[part 2 of 2: packages /BMW/Boardnet/Clusters/CommunicationClusters to /BMW/Boardnet/Pdus/PDUs]
AUTOSAR XML (schema 4-2-2)
package /BMW/Boardnet/Clusters/CommunicationClusters  (continued)
  flexray cluster A_FlexRay:  (continued)
    flexray physical channel A_FlexRay: comm-connectors=con_EPS_FibexID_0b7e5e09c061465d913e8968ece3cded, channel-name=CHANNEL-A  (continued)
      frame xcpdynamic254_2: from EPS, category=XCP_RUNTIME_CONFIGURED, frame-length=254, flexray-absolutely-scheduled-timing{communication-cycle=cycle-repetition={base-cycle=0, cycle-repetition=CYCLE-REPETITION-1}, slot-id=295}, allow-dynamic-l-sdu-length=false, payload-preamble-indicator=false  # XCP-Bereich dynamic 254 Bytes 2 | XCP-Frame (Runtime-Configured) für die Kommunikation zwischen Master und Slaves. Maximal zulässige Größe ist 254 Bytes. Wichtig: Die FIBEX-Framegröße stellt keine Spezifikation dar sondern bildet lediglich die protokolltechnisch maximal erlaubte Größe. Die Framegröße muss durch den Anwender im a2l-File festgelegt werden. Dabei muss auch die ECU-spezifische Controllerkonfiguration beachtet werden. Sende-/Empfangsbeziehungen im FIBEX dürfen nicht ausgewertet werden und sind ebenfalls keine verbindliche Spezifikation.
        general purpose i pdu xcpdynamic254_2: category=XCP, length=254  # XCP-Bereich dynamic 254 Bytes 2 | Die PDU (254 Byte lang) hat ebenso keine inhaltliche Verbindlichkeit.
      frame xcpdynamic254_3: from EPS, category=XCP_RUNTIME_CONFIGURED, frame-length=254, flexray-absolutely-scheduled-timing{communication-cycle=cycle-repetition={base-cycle=0, cycle-repetition=CYCLE-REPETITION-1}, slot-id=296}, allow-dynamic-l-sdu-length=false, payload-preamble-indicator=false  # XCP-Bereich dynamic 254 Bytes 3 | XCP-Frame (Runtime-Configured) für die Kommunikation zwischen Master und Slaves. Maximal zulässige Größe ist 254 Bytes. Wichtig: Die FIBEX-Framegröße stellt keine Spezifikation dar sondern bildet lediglich die protokolltechnisch maximal erlaubte Größe. Die Framegröße muss durch den Anwender im a2l-File festgelegt werden. Dabei muss auch die ECU-spezifische Controllerkonfiguration beachtet werden. Sende-/Empfangsbeziehungen im FIBEX dürfen nicht ausgewertet werden und sind ebenfalls keine verbindliche Spezifikation.
        general purpose i pdu xcpdynamic254_3: category=XCP, length=254  # XCP-Bereich dynamic 254 Bytes 3 | Die PDU (254 Byte lang) hat ebenso keine inhaltliche Verbindlichkeit.
      frame xcpdynamic254_4: from EPS, category=XCP_RUNTIME_CONFIGURED, frame-length=254, flexray-absolutely-scheduled-timing{communication-cycle=cycle-repetition={base-cycle=0, cycle-repetition=CYCLE-REPETITION-1}, slot-id=297}, allow-dynamic-l-sdu-length=false, payload-preamble-indicator=false  # XCP-Bereich dynamic 254 Bytes 4 | XCP-Frame (Runtime-Configured) für die Kommunikation zwischen Master und Slaves. Maximal zulässige Größe ist 254 Bytes. Wichtig: Die FIBEX-Framegröße stellt keine Spezifikation dar sondern bildet lediglich die protokolltechnisch maximal erlaubte Größe. Die Framegröße muss durch den Anwender im a2l-File festgelegt werden. Dabei muss auch die ECU-spezifische Controllerkonfiguration beachtet werden. Sende-/Empfangsbeziehungen im FIBEX dürfen nicht ausgewertet werden und sind ebenfalls keine verbindliche Spezifikation.
        general purpose i pdu xcpdynamic254_4: category=XCP, length=254  # XCP-Bereich dynamic 254 Bytes 4 | Die PDU (254 Byte lang) hat ebenso keine inhaltliche Verbindlichkeit.
      frame xcpdynamic254_5: from EPS, category=XCP_RUNTIME_CONFIGURED, frame-length=254, flexray-absolutely-scheduled-timing{communication-cycle=cycle-repetition={base-cycle=0, cycle-repetition=CYCLE-REPETITION-1}, slot-id=298}, allow-dynamic-l-sdu-length=false, payload-preamble-indicator=false  # XCP-Bereich dynamic 254 Bytes 5 | XCP-Frame (Runtime-Configured) für die Kommunikation zwischen Master und Slaves. Maximal zulässige Größe ist 254 Bytes. Wichtig: Die FIBEX-Framegröße stellt keine Spezifikation dar sondern bildet lediglich die protokolltechnisch maximal erlaubte Größe. Die Framegröße muss durch den Anwender im a2l-File festgelegt werden. Dabei muss auch die ECU-spezifische Controllerkonfiguration beachtet werden. Sende-/Empfangsbeziehungen im FIBEX dürfen nicht ausgewertet werden und sind ebenfalls keine verbindliche Spezifikation.
        general purpose i pdu xcpdynamic254_5: category=XCP, length=254  # XCP-Bereich dynamic 254 Bytes 5 | Die PDU (254 Byte lang) hat ebenso keine inhaltliche Verbindlichkeit.
      frame xcpdynamic254_6: from EPS, category=XCP_RUNTIME_CONFIGURED, frame-length=254, flexray-absolutely-scheduled-timing{communication-cycle=cycle-repetition={base-cycle=0, cycle-repetition=CYCLE-REPETITION-1}, slot-id=299}, allow-dynamic-l-sdu-length=false, payload-preamble-indicator=false  # XCP-Bereich dynamic 254 Bytes 6 | XCP-Frame (Runtime-Configured) für die Kommunikation zwischen Master und Slaves. Maximal zulässige Größe ist 254 Bytes. Wichtig: Die FIBEX-Framegröße stellt keine Spezifikation dar sondern bildet lediglich die protokolltechnisch maximal erlaubte Größe. Die Framegröße muss durch den Anwender im a2l-File festgelegt werden. Dabei muss auch die ECU-spezifische Controllerkonfiguration beachtet werden. Sende-/Empfangsbeziehungen im FIBEX dürfen nicht ausgewertet werden und sind ebenfalls keine verbindliche Spezifikation.
        general purpose i pdu xcpdynamic254_6: category=XCP, length=254  # XCP-Bereich dynamic 254 Bytes 6 | Die PDU (254 Byte lang) hat ebenso keine inhaltliche Verbindlichkeit.
      frame xcpdynamic254_7: from EPS, category=XCP_RUNTIME_CONFIGURED, frame-length=254, flexray-absolutely-scheduled-timing{communication-cycle=cycle-repetition={base-cycle=0, cycle-repetition=CYCLE-REPETITION-1}, slot-id=300}, allow-dynamic-l-sdu-length=false, payload-preamble-indicator=false  # XCP-Bereich dynamic 254 Bytes 7 | XCP-Frame (Runtime-Configured) für die Kommunikation zwischen Master und Slaves. Maximal zulässige Größe ist 254 Bytes. Wichtig: Die FIBEX-Framegröße stellt keine Spezifikation dar sondern bildet lediglich die protokolltechnisch maximal erlaubte Größe. Die Framegröße muss durch den Anwender im a2l-File festgelegt werden. Dabei muss auch die ECU-spezifische Controllerkonfiguration beachtet werden. Sende-/Empfangsbeziehungen im FIBEX dürfen nicht ausgewertet werden und sind ebenfalls keine verbindliche Spezifikation.
        general purpose i pdu xcpdynamic254_7: category=XCP, length=254  # XCP-Bereich dynamic 254 Bytes 7 | Die PDU (254 Byte lang) hat ebenso keine inhaltliche Verbindlichkeit.
      frame xcpdynamic254_8: from EPS, category=XCP_RUNTIME_CONFIGURED, frame-length=254, flexray-absolutely-scheduled-timing{communication-cycle=cycle-repetition={base-cycle=0, cycle-repetition=CYCLE-REPETITION-1}, slot-id=301}, allow-dynamic-l-sdu-length=false, payload-preamble-indicator=false  # XCP-Bereich dynamic 254 Bytes 8 | XCP-Frame (Runtime-Configured) für die Kommunikation zwischen Master und Slaves. Maximal zulässige Größe ist 254 Bytes. Wichtig: Die FIBEX-Framegröße stellt keine Spezifikation dar sondern bildet lediglich die protokolltechnisch maximal erlaubte Größe. Die Framegröße muss durch den Anwender im a2l-File festgelegt werden. Dabei muss auch die ECU-spezifische Controllerkonfiguration beachtet werden. Sende-/Empfangsbeziehungen im FIBEX dürfen nicht ausgewertet werden und sind ebenfalls keine verbindliche Spezifikation.
        general purpose i pdu xcpdynamic254_8: category=XCP, length=254  # XCP-Bereich dynamic 254 Bytes 8 | Die PDU (254 Byte lang) hat ebenso keine inhaltliche Verbindlichkeit.
      frame FR_DBG_EPS: from EPS, category=APPLICATION, frame-length=58, flexray-absolutely-scheduled-timing{communication-cycle=cycle-repetition={base-cycle=0, cycle-repetition=CYCLE-REPETITION-1}, slot-id=315}, allow-dynamic-l-sdu-length=false, payload-preamble-indicator=false  # FlexRay Debug EPS | Dieser Frame enthält nur Debugging-Informationen, die ausschließlich während der Entwicklungszeit übertragen werden dürfen. Kein Serienumfang! Der Frame darf nicht für andere Zwecke als Debugging verwendet werden. Für Messzweck ist ausschließlich XCP zu verwenden. Jedes FlexRay Steuergerät ist einen Debug-Frame zugewiesen. Falls kein Bedarf vorhanden, soll dieser Debug-Frame nicht gesendet werden. Das Senden der Frame soll über ein Codierschalter abschaltbar sein. Der Codierschalter sollte wie folgt definiert werden: C_DebugFrame_FR Die in dieser Frame enthaltene Signale dürfen von den Fachstellen geändert werden. Die hier vorgegebene maximale Länge und Zykluszeit gilt für den Basis-Modus (z.B. FIT Fahrzeug oder SA909). Der Basis-Modus darf ohne Abstimmung nicht erweitert werden (dient zur Sicherstellung der Bandbreite im FIT-Fahrzeuge). Falls die Notwendigkeit besteht mehr Daten schneller zu senden, darf dies in einem Extended-Modus stattfinden. Dieser Extended Modus muss über den Debug-Codierschalter ein- und ausschaltbar sein. Für den Codierschalter sollte folgende Codierung verwendet werden 0: nichts senden 1: senden Basis-Modus 2: senden Extended-Modus_1 (optional) Die Umsetzung des Modus Erweitert ist optional.
        multiplexed i pdu FR_DBG_EPS:  # FlexRay Debug EPS
          length=58
          dynamic-part{segment-position{segment-byte-order=little-endian, segment-length=464, segment-position=0}, dynamic-part-alternatives=[{i-pdu=DBG_EPS_BS_MOD_58_BYTE, initial-dynamic-part=true, selector-field-code=1}, {i-pdu=DBG_EPS_MOD_EXT_120_BYTE, initial-dynamic-part=false, selector-field-code=2}]}
          selector-field-byte-order=little-endian
          selector-field-length=8
          selector-field-start-position=0
          trigger-mode=DYNAMIC-PART-TRIGGER
          unused-bit-pattern=255
      frame AVL_RPM_WHL: to EPS, category=APPLICATION, frame-length=12, flexray-absolutely-scheduled-timing{communication-cycle=cycle-repetition={base-cycle=0, cycle-repetition=CYCLE-REPETITION-1}, slot-id=46}, allow-dynamic-l-sdu-length=false, payload-preamble-indicator=false  # Ist Drehzahl Rad
        pdu AVL_RPM_WHL: length=12, transmission-mode-true-timing=cyclic-timing=time-period=0.005, unused-bit-pattern=255  # Ist Drehzahl Rad | Die Nachricht beinhaltet die im DSC-Steuergerät eingelesenen Raddrehzahlen. Die Aufbereitung der Fahrzeuggeschwindigkeit erfolgt plausibilisiert im ICM-Q/L-Steuergerät. Zusätzlich wird basierend auf den Raddrehzahlen eine Schlechtwegeerkennung in der Motorsteuerung durchgeführt. Die PDU "Ist Drehzahl Rad" wird auf CAN durch die PDUs "Ist Drehzahl Rad ungesichert" und "Ist Drehzahl Rad Qualifier" abgebildet. "Ist Drehzahl Rad" ist nur am FlexRay vorhanden, "Ist Drehzahl Rad ungesichert" und "Ist Drehzahl Rad Qualifier" nur am CAN. Das Gateway (ZGW) setzt die Nachrichten entsprechend um. Bitte die Zusammenhänge bei Änderungen beachten, da zwischen den PDUs Abhängigkeit besteht. DMEs für Motoren vor dem B38 dürfen eine Unterabtastung der Nachricht durchführen.
          signal ALIV_AVL_RPM_WHL: start 8, 4 bit, little-endian, base-type=uint8, invalid-value=value_15Dot0:15, compu-method=ALIV_COU_4, to EPS  # Alive_Ist_Drehzahl_Rad / alive_actual-value_RPM_wheel | LogicalInterface:BMW.POWERTRAIN.SpeedAccelerationDistance[external]@Fahren;
          signal AVL_RPM_WHL_FLH: start 48, 16 bit, little-endian, base-type=uint16, invalid-value=value_65535Dot0:65535, compu {phys=raw/64-511.984375 for raw 491455..3768255; unit RadPerSec}, range phys 7167..58367 RadPerSec, to EPS  # Ist_Drehzahl_Rad_VL / actual-value_RPM_wheel_FLH | LogicalInterface:BMW.POWERTRAIN.SpeedAccelerationDistance[external]@Fahren; Gemessene Drehzahl des vorderen linken Einzelrads. Hinweis: Aufgrund der derzeitigen bei der Nachrichtenkataloggenerierung durch die IT bedingte Rundung von Nachkommastellen, werden die Offset- und Quantisierungswerte nicht korrekt wieder gegeben. Folgende Angaben entsprechen den exakten Werten: Offset = -511,984375 Quantisierung = 0,015625 Die Drehrichtungsinformation der Signale (Vorzeichen des übermittelten Wertes) ist zeitweise nicht verlässlich. Die Verlässlichkeit ist in den jeweiligen Status Qualifiern (Qualifier_Ist_Drehzahl_Rad_XX, nur in "Ist Drehzahl Rad" und "Ist Drehzahl Rad Qualifier" enthalten) angegeben. Nach Stillstand ist die Drehrichtung erst nach ca. 15cm Fahrstrecke plausibilisiert. Vorher wird immer der Ersatzwert (positiver Betrag) übertragen. In F25 und L7 gilt zusätzlich für Fahrzeuge mit Raddrehzahlfühler - ohne Drehrichtungserkennung wird der Wertebereich nur von 0 bis 400 rad/s befüllt - mit Drehrichtungserkennung wird der Wertebereich von -400 bis 400 rad/s befüllt Über die Dienstbotschaft (Anfrage ID 427 "Konfiguration DSC") kann das DSC aufgefordert werden die Informationen, welche Sensoren verbaut sind, zu senden. (Rückmeldung erfolgt über die Botschaft "Konfiguration DSC") Dieses Signal hat ein Äquivalent auf dem SF-CAN.
          signal AVL_RPM_WHL_FRH: start 64, 16 bit, little-endian, base-type=uint16, invalid-value=value_65535Dot0:65535, compu {phys=raw/64-511.984375 for raw 491455..3768255; unit RadPerSec}, range phys 7167..58367 RadPerSec, to EPS  # Ist_Drehzahl_Rad_VR / actual-value_RPM_wheel_FRH | LogicalInterface:BMW.POWERTRAIN.SpeedAccelerationDistance[external]@Fahren; Gemessene Drehzahl des vorderen rechten Einzelrads. Hinweis: Aufgrund der derzeitigen bei der Nachrichtenkataloggenerierung durch die IT bedingte Rundung von Nachkommastellen, werden die Offset- und Quantisierungswerte nicht korrekt wieder gegeben. Folgende Angaben entsprechen den exakten Werten: Offset = -511,984375 Quantisierung = 0,015625 Die Drehrichtungsinformation der Signale (Vorzeichen des übermittelten Wertes) ist zeitweise nicht verlässlich. Die Verlässlichkeit ist in den jeweiligen Status Qualifiern (Qualifier_Ist_Drehzahl_Rad_XX, nur in "Ist Drehzahl Rad" und "Ist Drehzahl Rad Qualifier" enthalten) angegeben. Nach Stillstand ist die Drehrichtung erst nach ca. 15cm Fahrstrecke plausibilisiert. Vorher wird immer der Ersatzwert (positiver Betrag) übertragen. In F25 und L7 gilt zusätzlich für Fahrzeuge mit Raddrehzahlfühler - ohne Drehrichtungserkennung wird der Wertebereich nur von 0 bis 400 rad/s befüllt - mit Drehrichtungserkennung wird der Wertebereich von -400 bis 400 rad/s befüllt Über die Dienstbotschaft (Anfrage ID 427 "Konfiguration DSC") kann das DSC aufgefordert werden die Informationen, welche Sensoren verbaut sind, zu senden. (Rückmeldung erfolgt über die Botschaft "Konfiguration DSC") Dieses Signal hat ein Äquivalent auf dem SF-CAN.
          signal AVL_RPM_WHL_RLH: start 16, 16 bit, little-endian, base-type=uint16, invalid-value=value_65535Dot0:65535, compu {phys=raw/64-511.984375 for raw 491455..3768255; unit RadPerSec}, range phys 7167..58367 RadPerSec, to EPS  # Ist_Drehzahl_Rad_HL / actual-value_RPM_wheel_RLH | LogicalInterface:BMW.POWERTRAIN.SpeedAccelerationDistance[external]@Fahren; Gemessene Drehzahl des hinteren linken Einzelrads. Hinweis: Aufgrund der derzeitigen bei der Nachrichtenkataloggenerierung durch die IT bedingte Rundung von Nachkommastellen, werden die Offset- und Quantisierungswerte nicht korrekt wieder gegeben. Folgende Angaben entsprechen den exakten Werten: Offset = -511,984375 Quantisierung = 0,015625 Die Drehrichtungsinformation der Signale (Vorzeichen des übermittelten Wertes) ist zeitweise nicht verlässlich. Die Verlässlichkeit ist in den jeweiligen Status Qualifiern (Qualifier_Ist_Drehzahl_Rad_XX, nur in "Ist Drehzahl Rad" und "Ist Drehzahl Rad Qualifier" enthalten) angegeben. Nach Stillstand ist die Drehrichtung erst nach ca. 15cm Fahrstrecke plausibilisiert. Vorher wird immer der Ersatzwert (positiver Betrag) übertragen. In F25 und L7 gilt zusätzlich für Fahrzeuge mit Raddrehzahlfühler - ohne Drehrichtungserkennung wird der Wertebereich nur von 0 bis 400 rad/s befüllt - mit Drehrichtungserkennung wird der Wertebereich von -400 bis 400 rad/s befüllt Über die Dienstbotschaft (Anfrage ID 427 "Konfiguration DSC") kann das DSC aufgefordert werden die Informationen, welche Sensoren verbaut sind, zu senden. (Rückmeldung erfolgt über die Botschaft "Konfiguration DSC")
          signal AVL_RPM_WHL_RRH: start 32, 16 bit, little-endian, base-type=uint16, invalid-value=value_65535Dot0:65535, compu {phys=raw/64-511.984375 for raw 491455..3768255; unit RadPerSec}, range phys 7167..58367 RadPerSec, to EPS  # Ist_Drehzahl_Rad_HR / actual-value_RPM_wheel_RRH | LogicalInterface:BMW.POWERTRAIN.SpeedAccelerationDistance[external]@Fahren; Gemessene Drehzahl des hinteren rechten Einzelrads. Hinweis: Aufgrund der derzeitigen bei der Nachrichtenkataloggenerierung durch die IT bedingte Rundung von Nachkommastellen, werden die Offset- und Quantisierungswerte nicht korrekt wieder gegeben. Folgende Angaben entsprechen den exakten Werten: Offset = -511,984375 Quantisierung = 0,015625 Die Drehrichtungsinformation der Signale (Vorzeichen des übermittelten Wertes) ist zeitweise nicht verlässlich. Die Verlässlichkeit ist in den jeweiligen Status Qualifiern (Qualifier_Ist_Drehzahl_Rad_XX, nur in "Ist Drehzahl Rad" und "Ist Drehzahl Rad Qualifier" enthalten) angegeben. Nach Stillstand ist die Drehrichtung erst nach ca. 15cm Fahrstrecke plausibilisiert. Vorher wird immer der Ersatzwert (positiver Betrag) übertragen. In F25 und L7 gilt zusätzlich für Fahrzeuge mit Raddrehzahlfühler - ohne Drehrichtungserkennung wird der Wertebereich nur von 0 bis 400 rad/s befüllt - mit Drehrichtungserkennung wird der Wertebereich von -400 bis 400 rad/s befüllt Über die Dienstbotschaft (Anfrage ID 427 "Konfiguration DSC") kann das DSC aufgefordert werden die Informationen, welche Sensoren verbaut sind, zu senden. (Rückmeldung erfolgt über die Botschaft "Konfiguration DSC")
          signal AVL_RPM_WHL_dummy_12_15: start 12, 4 bit, little-endian, init-value=15, base-type=uint8, compu {identical}, range phys 0..15, to EPS
          signal CRC_AVL_RPM_WHL: start 0, 8 bit, little-endian, base-type=uint8, compu-method=CRC8, data-constr=CRC8, to EPS  # CRC_Ist_Drehzahl_Rad / CRC_actual-value_RPM_wheel | LogicalInterface:BMW.POWERTRAIN.SpeedAccelerationDistance[external]@Fahren; Dieses Signal verwendet die Applikations-CRC-ID = 17 (Dez)
          signal QU_AVL_RPM_WHL_FLH: start 88, 4 bit, little-endian, base-type=uint8, invalid-value=value_15Dot0:15, compu-method=QU_AVL_RPM_WHL, to EPS  # Qualifier_Ist_Drehzahl_Rad_VL / Qualifier_actual-value_RPM_wheel_FLH | LogicalInterface:BMW.POWERTRAIN.SpeedAccelerationDistance[external]@Fahren; Status Qualifier zum Signal Ist_Drehzahl_Rad_VL. Ausführliche Spezifikation der Qualifier ist im Komponenten Lastenheften DSC und IPM zu finden. Dieses Signal hat ein Äquivalent auf dem SF-CAN.
          signal QU_AVL_RPM_WHL_FRH: start 92, 4 bit, little-endian, base-type=uint8, invalid-value=value_15Dot0:15, compu-method=QU_AVL_RPM_WHL, to EPS  # Qualifier_Ist_Drehzahl_Rad_VR / Qualifier_actual-value_RPM_wheel_FRH | LogicalInterface:BMW.POWERTRAIN.SpeedAccelerationDistance[external]@Fahren; Status Qualifier zum Signal Ist_Drehzahl_Rad_VR. Ausführliche Spezifikation der Qualifier ist im Komponenten Lastenheften DSC und IPM zu finden. Dieses Signal hat ein Äquivalent auf dem SF-CAN.
          signal QU_AVL_RPM_WHL_RLH: start 80, 4 bit, little-endian, base-type=uint8, invalid-value=value_15Dot0:15, compu-method=QU_AVL_RPM_WHL, to EPS  # Qualifier_Ist_Drehzahl_Rad_HL / Qualifier_actual-value_RPM_wheel_RLH | LogicalInterface:BMW.POWERTRAIN.SpeedAccelerationDistance[external]@Fahren; Status Qualifier zum Signal Ist_Drehzahl_Rad_HL. Ausführliche Spezifikation der Qualifier ist im Komponenten Lastenheften DSC und IPM zu finden.
          signal QU_AVL_RPM_WHL_RRH: start 84, 4 bit, little-endian, base-type=uint8, invalid-value=value_15Dot0:15, compu-method=QU_AVL_RPM_WHL, to EPS  # Qualifier_Ist_Drehzahl_Rad_HR / Qualifier_actual-value_RPM_wheel_RRH | LogicalInterface:BMW.POWERTRAIN.SpeedAccelerationDistance[external]@Fahren; Status Qualifier zum Signal Ist_Drehzahl_Rad_HR. Ausführliche Spezifikation der Qualifier ist im Komponenten Lastenheften DSC und IPM zu finden
          mapping sigGroup_AVL_RPM_WHL: i-signal-group=sigGroup_AVL_RPM_WHL
      frame ST_STAB_DSC_ST_STAB_DSC_2: to EPS, category=APPLICATION, frame-length=16, flexray-absolutely-scheduled-timing{communication-cycle=cycle-repetition={base-cycle=1, cycle-repetition=CYCLE-REPETITION-2}, slot-id=47}, allow-dynamic-l-sdu-length=false, payload-preamble-indicator=false  # Status Stabilisierung DSC / Status Stabilisierung DSC 2 | Statusinformation des DSC_Moduls.
        pdu ST_STAB_DSC: length=8, transmission-mode-true-timing=cyclic-timing=time-period=0.01, unused-bit-pattern=255  # Status Stabilisierung DSC | Statusinformation des DSC_Moduls.
          signal QU_FN_FDR: start 16, 12 bit, little-endian, base-type=uint16, invalid-value=value_4095Dot0:4095, compu {mask 3848: 512=FunktionVerfuegbarUndBereitNichtAktivSchlupfschwellenNormal (QU_FN_FDR_FunktionVerfuegbarUndBereitNichtAktivSchlupfschwellenNormal) (BNE original name: Funktion verfügbar und bereit, nicht aktiv, Schlupfschwellen normal), mask 3848: 520=FunktionVerfuegbarUndBereitNichtAktivSchlupfschwellenAufgeweitet (QU_FN_FDR_FunktionVerfuegbarUndBereitNichtAktivSchlupfschwellenAufgeweitet) (BNE original name: Funktion verfügbar und bereit, nicht aktiv, Schlupfschwellen aufgeweitet), mask 3848: 2560=FunktionVerfuegbarUndAktivSchlupfschwellenNormal (QU_FN_FDR_FunktionVerfuegbarUndAktivSchlupfschwellenNormal) (BNE original name: Funktion verfügbar und aktiv, Schlupfschwellen normal), mask 3848: 2568=FunktionVerfuegbarUndAktivSchlupfschwellenAufgeweitet (QU_FN_FDR_FunktionVerfuegbarUndAktivSchlupfschwellenAufgeweitet) (BNE original name: Funktion verfügbar und aktiv, Schlupfschwellen aufgeweitet), mask 3848: 768=reserviert (QU_FN_FDR_reserviert_DUPLICATE4275619181), mask 3848: 776=reserviert_bne_13C341D8A98349C2A0E5CFC9373CD7D4_776 (QU_FN_FDR_reserviert_bne_13C341D8A98349C2A0E5CFC9373CD7D4_776) (BNE original name: reserviert), mask 3856: 2576=FunktionVerfuegbarUndAktivFDRRegeleingriffVL (QU_FN_FDR_FunktionVerfuegbarUndAktivFDRRegeleingriffVL) (BNE original name: Funktion verfügbar und aktiv, FDR Regeleingriff VL), mask 3872: 2592=FunktionVerfuegbarUndAktivFDRRegeleingriffVR (QU_FN_FDR_FunktionVerfuegbarUndAktivFDRRegeleingriffVR) (BNE original name: Funktion verfügbar und aktiv, FDR Regeleingriff VR), mask 3904: 2624=FunktionVerfuegbarUndAktivFDRRegeleingriffHL (QU_FN_FDR_FunktionVerfuegbarUndAktivFDRRegeleingriffHL) (BNE original name: Funktion verfügbar und aktiv, FDR Regeleingriff HL), mask 3968: 2688=FunktionVerfuegbarUndAktivFDRRegeleingriffHR (QU_FN_FDR_FunktionVerfuegbarUndAktivFDRRegeleingriffHR) (BNE original name: Funktion verfügbar und aktiv, FDR Regeleingriff HR), mask 3840: 1536=FunktionNichtVerfuegbarColonFehler (QU_FN_FDR_FunktionNichtVerfuegbarColonFehler) (BNE original name: Funktion nicht verfügbar: Fehler), mask 3840: 3584=FunktionNichtVerfuegbarColonAusgeschaltet (QU_FN_FDR_FunktionNichtVerfuegbarColonAusgeschaltet) (Diese Codierung wird versendet wenn mind. eine dieser Bedingungen erfüllt ist: Initialisierungsphase des SG (Vorbefüllung), Zündung=aus, Motorstart, INITAusblendung aktiv, Funktion über DTC-Taster deaktiviert / BNE original name: Funktion nicht verfügbar: Ausgeschaltet), mask 3840: 2048=reserviert (QU_FN_FDR_reserviert_DUPLICATE1945092900), mask 3840: 512=reserviert_bne_13C341D8A98349C2A0E5CFC9373CD7D4_512 (QU_FN_FDR_reserviert_bne_13C341D8A98349C2A0E5CFC9373CD7D4_512) (BNE original name: reserviert), mask 4095: 4095=SignalUngueltig (QU_FN_FDR_SignalUngueltig) (Nutzung nur vom Gateway, nicht seitens Sender-SG / BNE original name: Signal ungültig)} "Qualifier_Funktion_FDR / Qualifier_function_FDR", to EPS  # Qualifier_Funktion_FDR / Qualifier_function_FDR | LogicalInterface:BMW.CHASSIS.STABILIZATION.VehicleStabilizationManagement[external]@Fahren; Funktions-Qualifier zur FDR. Die untersten 3 Bits dieses Signals können vom DSC für Entwicklungszwecke belegt werden, sind aber nicht auszuwerten. Weitere Details finden sich im DSC-KomponentenLH
      frame AVL_STMOM_DV_ACT_AVL_FORC_GRD: from EPS, category=APPLICATION, frame-length=16, flexray-absolutely-scheduled-timing{communication-cycle=cycle-repetition={base-cycle=0, cycle-repetition=CYCLE-REPETITION-2}, slot-id=49}, allow-dynamic-l-sdu-length=false, payload-preamble-indicator=false  # Ist Lenkmoment Fahrer Stellglied / Ist Kraft Zahnstange / actual-value steering-moment driver actuator / Ist Kraft Zahnstange | Dieser Frame setzt sich zusammen aus den PDUs Ist Lenkmoment Fahrer Stellglied und Ist Kraft Zahnstange.
        carries pdu AVL_FORC_GRD: packing-byte-order=little-endian, start-position=64
        pdu AVL_FORC_GRD: length=5, transmission-mode-true-timing=cyclic-timing=time-period=0.01, unused-bit-pattern=255  # Ist Kraft Zahnstange | Die angegebene Zahnstangenkraft ist eine aus dem Zustandsbeobachter geschätzte Grösse. Dieser Frame ist Teil der KOM-Schnittstelle Lenkradmomentenregler des OEL-Reglers. Diese Version der Nachricht gilt bis SP2013.
          signal ALIV_AVL_FORC_GRD: start 8, 4 bit, little-endian, base-type=uint8, invalid-value=value_15Dot0:15, compu-method=ALIV_COU_4  # Alive_Ist_Kraft_Zahnstange / alive_actual-value_force_gear-rod | LogicalInterface:BMW.CHASSIS.STEERING.ElectricPowerSteering[internal]@Fahren; Standardabsicherung Alivezähler laut Definition per Lastenheft Allgemeine Bordnetzkommunikation.
          signal AVL_FORC_GRD: start 16, 12 bit, little-endian, base-type=uint16, invalid-value=value_4095Dot0:4095, compu {phys=raw*0.0084-17 for raw 2023.8095238095239..483883.2199546486; unit kilonewton}, range phys 0..4047.619 kilonewton  # Ist_Kraft_Zahnstange / actual-value_force_gear-rod | LogicalInterface:BMW.CHASSIS.STEERING.ElectricPowerSteering[internal]@Fahren; Die angegebene Zahnstangenkraft (aus dem Zustandsbeobachter geschätzte Größe) spiegelt die Ist-Kraft der Zahnstange (EPS + Fahrer) wieder. Die Zahnstangenkraft ist bei einer Bewegung des Lenkrads aus seiner Nulllage entgegen des Uhrzeigersinns positiv.
          signal AVL_FORC_GRD_dummy_12_15: start 12, 4 bit, little-endian, init-value=15, base-type=uint8, compu {identical}, range phys 0..15
          signal AVL_PWR_EL_EPS_COOD: start 32, 8 bit, little-endian, base-type=uint8, invalid-value=value_255Dot0:255, compu {phys=raw*0.1-12 for raw 120..2520; unit kilowatt}, range phys 0..240 kilowatt  # Ist_Leistung_Elektrisch_EPS_Koordinator / actual-value_power_electric_EPS_coordinator | LogicalInterface:BMW.CHASSIS.STEERING.ElectricPowerSteering[internal]@Fahren;
          signal CRC_AVL_FORC_GRD: start 0, 8 bit, little-endian, base-type=uint8, compu-method=CRC8, data-constr=CRC8  # CRC_Ist_Kraft_Zahnstange / CRC_actual-value_force_gear-rod | LogicalInterface:BMW.CHASSIS.STEERING.ElectricPowerSteering[internal]@Fahren; Standardabsicherung Applikations-CRC Dieses Signal verwendet die Applikations-CRC-ID = 190 (Dez)
          signal QU_AVL_FORC_GRD: start 28, 4 bit, little-endian, base-type=uint8, invalid-value=value_15Dot0:15, compu {8=Initialisierung (QU_AVL_FORC_GRD_Initialisierung) (At the startup of the TSU driver. Nutzsignal wird permanent mit 0,0016 befüllt.), 2=SignalwertIstGueltig (QU_AVL_FORC_GRD_SignalwertIstGueltig) (The signal is valid since every input signal is valid FUSI: Do not use for safety critical functions / BNE original name: Signalwert ist gültig), 14=SignalwertIstUngueltigZustandSlashStatusTemporaer (QU_AVL_FORC_GRD_SignalwertIstUngueltigZustandSlashStatusTemporaer) (The signal is invalid since one of the input signals is invalid. Das zugehörige Nutzsignal wird permanent mit der Ungültigkeitskennung befüllt. / BNE original name: Signalwert ist ungültig, Zustand/Status temporär), 15=SignalUngueltig (QU_AVL_FORC_GRD_SignalUngueltig) (Kann Funktional nicht gesetzt werden / BNE original name: Signal ungültig)} "Qualifier_Ist_Kraft_Zahnstange / Qualifier_actual-value_force_gear-rod"  # Qualifier_Ist_Kraft_Zahnstange / Qualifier_actual-value_force_gear-rod | LogicalInterface:BMW.CHASSIS.STEERING.ElectricPowerSteering[internal]@Fahren; Erweiterter Qualifier zum Signal Ist_Kraft_Zahnstange
          mapping sigGroup_AVL_FORC_GRD: i-signal-group=sigGroup_AVL_FORC_GRD
        pdu AVL_STMOM_DV_ACT: length=4, transmission-mode-true-timing=cyclic-timing=time-period=0.01, unused-bit-pattern=255  # Ist Lenkmoment Fahrer Stellglied / actual-value steering-moment driver | Darstellung des Fahrerhandmoment. Diese Version der Nachricht gilt bis SP2013.
          signal ALIV_AVL_STMOM_DV_ACT: start 8, 4 bit, little-endian, base-type=uint8, invalid-value=value_15Dot0:15, compu-method=ALIV_COU_4  # Alive_Ist_Lenkmoment_Fahrer_Stellglied / alive_actual-value_steering-moment_driver_actuator | LogicalInterface:BMW.CHASSIS.STEERING.ElectricPowerSteering[external]@Fahren; Standardabsicherung Alivezähler laut Definition per Lastenheft Allgemeine Bordnetzkommunikation.
          signal AVL_STMOM_DV_ACT: start 16, 12 bit, little-endian, base-type=uint16, invalid-value=value_4095Dot0:4095, compu {phys=raw*0.005-10 for raw 2000..802000; unit NwtMtr}, range phys 0..4000 NwtMtr  # Ist_Lenkmoment_Fahrer_Stellglied / actual-value_steering-moment_driver_actuator | LogicalInterface:BMW.CHASSIS.STEERING.ElectricPowerSteering[external]@Fahren; Das Signal Ist_Lenkmoment_Fahrer stellt das Fahrerlenkmoment im Gegenuhrzeigersinn positiv dar.
          signal AVL_STMOM_DV_ACT_dummy_12_15: start 12, 4 bit, little-endian, init-value=15, base-type=uint8, compu {identical}, range phys 0..15
          signal CRC_AVL_STMOM_DV_ACT: start 0, 8 bit, little-endian, base-type=uint8, compu-method=CRC8, data-constr=CRC8  # CRC_Ist_Lenkmoment_Fahrer_Stellglied / CRC_actual-value_steering-moment_driver_actuator | LogicalInterface:BMW.CHASSIS.STEERING.ElectricPowerSteering[external]@Fahren; Standardabsicherung Applikations-CRC laut Definition per Lastenheft Allgemeine Bordnetzkommunikation. Dieses Signal verwendet die Applikations-CRC-ID = 108 (Dez)
          signal QU_AVL_STMOM_DV_ACT: start 28, 4 bit, little-endian, base-type=uint8, invalid-value=value_15Dot0:15, compu {8=Initialisierung (QU_AVL_STMOM_DV_ACT_Initialisierung) (Tritt während der Initialisierungsphase auf (Vorbefüllung). Nutzsignal wird permanent mit Nutzwert 0 befüllt.), 1=SignalwertIstGueltigUndAbgesichertUndPlausibilisiert (QU_AVL_STMOM_DV_ACT_SignalwertIstGueltigUndAbgesichertUndPlausibilisiert) (The TSU works properly and the two torque signals are close enough to be plausible / BNE original name: Signalwert ist gültig und abgesichert und plausibilisiert), 14=SignalwertIstUngueltigZustandSlashStatusTemporaer (QU_AVL_STMOM_DV_ACT_SignalwertIstUngueltigZustandSlashStatusTemporaer) (Das zugehörige Nutzsignal wird permanent mit der Ungültigkeitskennung befüllt. The communication with the TSU or the TSU itself is wrong or because of some other reason the TSU signals are not good Wird in der L6 nicht verwendet / BNE original name: Signalwert ist ungültig, Zustand/Status temporär), 6=SignalwertIstUngueltig (QU_AVL_STMOM_DV_ACT_SignalwertIstUngueltig) (Wird in der L6 verwendet für die Ungültigkeitskennung des Signalwert Das zugehörige Nutzsignal wird permanent mit der Ungültigkeitskennung befüllt. / BNE original name: Signalwert ist ungültig), 15=SignalUngueltig (QU_AVL_STMOM_DV_ACT_SignalUngueltig) (Wird funktional nicht versendet / BNE original name: Signal ungültig)} "Qualifier_Ist_Lenkmoment_Fahrer_Stellglied / Qualifier_actual-value_steering-moment_driver_actuator"  # Qualifier_Ist_Lenkmoment_Fahrer_Stellglied / Qualifier_actual-value_steering-moment_driver_actuator | LogicalInterface:BMW.CHASSIS.STEERING.ElectricPowerSteering[external]@Fahren; Erweiterter Status Qualifier zum Signal Ist_Lenkmoment_Fahrer_Stellglied
          mapping sigGroup_AVL_STMOM_DV_ACT: i-signal-group=sigGroup_AVL_STMOM_DV_ACT
      frame DT_EST: from EPS, category=APPLICATION, frame-length=16, flexray-absolutely-scheduled-timing{communication-cycle=cycle-repetition={base-cycle=1, cycle-repetition=CYCLE-REPETITION-2}, slot-id=49}, allow-dynamic-l-sdu-length=false, payload-preamble-indicator=false  # Daten Elektrische-Lenkung
        pdu DT_EST: length=16, transmission-mode-true-timing=cyclic-timing=time-period=0.01, unused-bit-pattern=255  # Daten Elektrische-Lenkung
          signal ALIV_DT_EST: start 8, 4 bit, little-endian, base-type=uint8, invalid-value=value_15Dot0:15, compu {identical}, range phys 0..14  # Alive_Daten_Elektrische-Lenkung / alive_data_electrical-steering | LogicalInterface:BMW.CHASSIS.STEERING.ElectricPowerSteering[internal]@Fahren; Standardabsicherung Alivezähler laut Definition per Lastenheft Allgemeine Bordnetzkommunikation Dieses Signal soll nur überwacht werden, wenn Aktivlenkung und ein Lenksäulensteller verbaut sind.
          signal AVL_I_ACT_EST: start 48, 8 bit, little-endian, base-type=uint8, invalid-value=value_255Dot0:255, compu-method=I_SPEC_ARS, data-constr=I_SPEC_ARS  # Ist_Strom_Stellglied_Elektrische-Lenkung / actual-value_current_actuator_electrical-steering | LogicalInterface:BMW.CHASSIS.LOWVOLTAGE.EnergyManagementELMa[internal]@Fahren; Es handelt sich um den DC-Last-Strom am Stecker der elektrischen Lenkmomentenunterstützung (EPS-Motor). Der Strom ist über einen FR-Task gemittelt. Aufstart- und Default-Wert ist 0 A.
          signal CRC_DT_EST: start 0, 8 bit, little-endian, base-type=uint8, compu-method=CRC8, data-constr=CRC8  # CRC_Daten_Elektrische-Lenkung / CRC_data_electrical-steering | LogicalInterface:BMW.CHASSIS.STEERING.ElectricPowerSteering[internal]@Fahren; Standardabsicherung Applikations-CRC laut Definition per Lastenheft Allgemeine Bordnetzkommunikation. Dieses Signal verwendet die Applikations-CRC-ID = 230 (dec) Dieses Signal soll nur überwacht werden, wenn Aktivlenkung und ein Lenksäulensteller verbaut sind.
          signal DT_EST_dummy_12_15: start 12, 4 bit, little-endian, init-value=15, base-type=uint8, compu {identical}, range phys 0..15
          signal DT_EST_dummy_16_47: start 16, 32 bit, little-endian, init-value=4294967295, base-type=uint32, compu {identical}, range phys 0..4294967295
          signal DT_EST_dummy_64_95: start 64, 32 bit, little-endian, init-value=4294967295, base-type=uint32, compu {identical}, range phys 0..4294967295
          signal DT_EST_dummy_96_127: start 96, 32 bit, little-endian, init-value=4294967295, base-type=uint32, compu {identical}, range phys 0..4294967295
          signal QU_AVL_I_ACT_EST: start 60, 4 bit, little-endian, base-type=uint8, invalid-value=value_15Dot0:15, compu {1=Wert_gueltig_abgesichert (QU_SUM_AVL_I_DRDY_SFY_Wert_gueltig_abgesichert) (Stromwert gueltig und abgesichert), 3=Wert_gueltig_eingeschraenkt (QU_SUM_AVL_I_DRDY_SFY_Wert_gueltig_eingeschraenkt) (Stromwert nicht abgesichert), 6=Wert_nicht_verfuegbar_Fehler (QU_SUM_AVL_I_DRDY_SFY_Wert_nicht_verfuegbar_Fehler) (Sendefunktion in Betrieb, Werte nicht verfügbar), 14=Wert_nicht_verfuegbar (QU_SUM_AVL_I_DRDY_SFY_Wert_nicht_verfuegbar) (Sendefunktion in Betrieb, meldet Fehler), 15=Signal_unbefuellt (QU_SUM_AVL_I_DRDY_SFY_Signal_unbefuellt) (Sendefunktion nicht in Betrieb)} "Qualifier_Summe_Ist_Strom_Fahrdynamik_Sicherheit / Qualifier_sum_actual-value_current_driving-dynamics_safety"  # Qualifier_Ist_Strom_Stellglied_Elektrische-Lenkung / Qualifier_actual-value_current_actuator_electrical-steering | LogicalInterface:BMW.POWERTRAIN.GENERATOR.EnergySupplySafe[internal]@Fahren; Signalqualifier zum Signal Ist_Strom_Stellglied_Elektrische-Lenkung.
          signal ST_CULI_EST: start 56, 4 bit, little-endian, base-type=uint8, invalid-value=value_15Dot0:15, compu {0=Keine_Strombegrenzung (ST_CULI_EST_Keine_Strombegrenzung) (Keine Strombegrenzung aktiv.), 1=Komfort_Strombegrenzung (ST_CULI_EST_Komfort_Strombegrenzung) (Strombegrenzung über ELMa aktiv.), 10=Maximale_Strombegrenzung (ST_CULI_EST_Maximale_Strombegrenzung) (Sicherheits-Strombegrenzung aktiv), 13=Reserviert_nicht_verfuegbar (ST_CULI_EST_Reserviert_nicht_verfuegbar) (Hinweis: Reserviert für funktionale Kennung Signal-Tag.), 14=Reserviert_Fehler (ST_CULI_EST_Reserviert_Fehler) (Hinweis: Reserviert für funktionale Kennung Signal-Tag.), 15=Signal_unbefuellt (ST_CULI_EST_Signal_unbefuellt) (Sendefunktion nicht in Betrieb)} "Status_Strombegrenzung_Elektrische-Lenkung / status_current-limitation_electrical-steering"  # Status_Strombegrenzung_Elektrische-Lenkung / status_current-limitation_electrical-steering | LogicalInterface:BMW.POWERTRAIN.GENERATOR.EnergySupplySafe[internal]@Fahren; In diesem Signal wird übermittelt, ob und in welchem Umfang eine Strombegrenzung an der Elektrischen Lenkung umgesetzt wurde.
          mapping sigGroup_DT_EST: i-signal-group=sigGroup_DT_EST
      frame AVL_PO_EPS_ENGTORQ_EPS: from EPS, category=APPLICATION, frame-length=16, flexray-absolutely-scheduled-timing{communication-cycle=cycle-repetition={base-cycle=0, cycle-repetition=CYCLE-REPETITION-2}, slot-id=51}, allow-dynamic-l-sdu-length=false, payload-preamble-indicator=false  # Ist Position EPS / Motormoment EPS
        pdu AVL_PO_EPS: length=8, transmission-mode-true-timing=cyclic-timing=time-period=0.01, unused-bit-pattern=255  # Ist Position EPS | Die Nachricht enthält die EPS-Position, berechnet aus dem aufintegrierten EPS-Rotorlagewinkel. Diese Größe dient als Eingangsgröße für die aufbereiteten Lenkwinkel Nachrichten "Ist Lenkwinkel Fahrer", "Ist Lenkwinkel Vorderachse" und "Lenkwinkel Vorderachse Effektiv".
          signal ALIV_AVL_PO_EPS: start 8, 4 bit, little-endian, base-type=uint8, invalid-value=value_15Dot0:15, compu-method=ALIV_COU_4  # Alive_Ist_Position_EPS / alive_actual-value_position_EPS | LogicalInterface:BMW.CHASSIS.STEERING.ElectricPowerSteering[internal]@Fahren;
          signal AVL_PO_EPS: start 16, 16 bit, little-endian, base-type=uint16, invalid-value=value_65535Dot0:65535, compu {phys=raw*0.0439453125-1439.956055 for raw 32767..1524029.5777777778}, range phys 0..65534  # Ist_Position_EPS / actual-value_position_EPS | LogicalInterface:BMW.CHASSIS.STEERING.ElectricPowerSteering[internal]@Fahren; Relative Position, berechnet aus dem aufintegrierten EPS-Rotorlagewinkel, bezogen auf den aktuellen Nullpunkt der EPS (entspricht der Segmentmitte des Segments in dem sich der EPS-Rotor z.B. nach dem letzten Einbruch der Spannungsversorgung befand), sofern mittels des Aufsetzalgorithmus der Offset des aktuellen Nullpunktes zum absoluten Nullpunkt (Segmentmitte des Segments bei Geradeausfahrt) noch nicht ermittelt werden konnte (zugehöriger Qualifier: "Ersatzwert ist im Nutzsignal gesetzt"). Sobald der Offset zum absoluten Nullpunkt bestimmt werden konnte und an die EPS übermittelt wurde, entspricht dieser dem absoluten Position (zugehöriger Qualifier: "Signalwert ist gültig"). Nach erfolgreicher EPS-interner Plausibilisierung wird der Qualifier auf "Signalwert ist gültig und abgesichert und plausibilisiert" gesetzt. Das Signal wird ohne Einheit übertragen. Die Einheit kann aus dem Signal "Einheit_Position_EPS" entnommen werden: - Im F25/L7 ist das Signal als Zahnstangenhub zu interpretieren. Die Einheit ist somit 0.2mm. Der Zahnstangenhub ist bei einer Bewegung des Lenkrads aus seiner Nulllage entgegen des Uhrzeigersinns positiv. Der zugehörige Signalstatus wird gebildet (Qualifier_Ist_Position_EPS). Die Informationen stehen bei Zündung ein oder fahrendem Fahrzeug mit vereinbarter Güte zur Verfügung Absicherung erfolgt durch Host-CRC und Alive-Zähler. Wert Bedeutung 0 Theoretisch maximaler Wert rechts 7FFF Geradeausstellung FFFE Thoretisch maximaler Wert links.
          signal AVL_PO_IDX_EPS: start 32, 16 bit, little-endian, base-type=uint16, invalid-value=value_65535Dot0:65535, compu {phys=raw*0.0439453125-1439.956055 for raw 32767..1524029.5777777778}, range phys 0..65534  # Ist_Position_Index_EPS / actual-value_position_index_EPS | LogicalInterface:BMW.CHASSIS.STEERING.ElectricPowerSteering[internal]@Fahren; Dieser Wert entspricht der aktuellen Position zum Zeitpunkt einer detektierten Indexflanke. Das Signal wird ohne Einheit übertragen. Die Einheit kann aus dem Signal "Einheit_Position_EPS" entnommen werden: - Im F25/L7 ist das Signal als Zahnstangenhub zu interpretieren. Die Einheit ist somit 0.2mm. Hinweis: Aufgrund der derzeitigen bei der Nachrichtenkataloggenerierung durch die IT bedingte Rundung von Nachkommastellen, werden die Offset- und Quantisierungswerte nicht korrekt wieder gegeben. Folgende Angaben entsprechen den exakten Werten: Offset = -1439,9560546875 Quantisierung = 0,0439453125
          signal CRC_AVL_PO_EPS: start 0, 8 bit, little-endian, base-type=uint8, compu-method=CRC8, data-constr=CRC8  # CRC_Ist_Position_EPS / CRC_actual-value_position_EPS | LogicalInterface:BMW.CHASSIS.STEERING.ElectricPowerSteering[internal]@Fahren; Standardabsicherung Applikations-CRC Dieses Signal verwendet die Applikations-CRC-ID = 186 (Dez)
          signal IDX_TORQ_SEN: start 60, 2 bit, little-endian, base-type=uint8, invalid-value=value_3Dot0:3, compu {0=Initialisierung (IDX_TORQ_SEN_Initialisierung), 1=KeineIndexFlanke (IDX_TORQ_SEN_KeineIndexFlanke) (FUSI: Verwendung im Funktionsrahmen zu prüfen. / BNE original name: Keine Index Flanke), 2=IndexFlanke (IDX_TORQ_SEN_IndexFlanke) (Gilt für steigende und fallende Flanken FUSI: Verwendung im Funktionsrahmen zu prüfen. / BNE original name: Index Flanke), 3=SignalUngueltig (IDX_TORQ_SEN_SignalUngueltig) (BNE original name: Signal ungültig)} "Index_Drehmoment_Sensor / index_torque_sensor"  # Index_Drehmoment_Sensor / index_torque_sensor | LogicalInterface:BMW.CHASSIS.STEERING.ElectricPowerSteering[internal]@Fahren; Information, ob das Lenkrad (bei nicht-AFS-Verbau, ansonsten Lenkgestänge "nach" AFS-Zustellaktuatorik) seit dem letzten Zyklus durch die 0° (=Geradeausfahrt), ±360° oder ±720° - Position bewegt worden ist.
          signal OFFS_GRD_MID_EPS: start 48, 12 bit, little-endian, base-type=uint16, invalid-value=value_4095Dot0:4095, compu {phys=raw*0.0439453125-89.95605469 for raw 2047..95208.24444444444}, range phys 0..4094  # Offset_Zahnstange_Mitte_EPS / offset_gear-rod_middle_EPS | LogicalInterface:BMW.CHASSIS.STEERING.ElectricPowerSteering[internal]@Fahren; Offset zwischen Zahnstangenmitte und dem Lenkwinkel-Nullpunkt (Geradeauslauf). Das Signal wird ohne Einheit übertragen. Die Einheit kann aus dem Signal "Einheit_Position_EPS" entnommen werden: - Im F25/L7 ist das Signal als Zahnstangenhub zu interpretieren. Die Einheit ist somit 0.2mm.
          signal QU_AVL_PO_EPS: start 12, 4 bit, little-endian, base-type=uint8, invalid-value=value_15Dot0:15, compu {8=Initialisierung (QU_AVL_PINA_EPS_Initialisierung) (Nach jedem Reset und Aufstarten des EPS-Steuergeräts. Nutzsignal wird permanent mit Nutzwert 0 befüllt.), 1=SignalwertIstGueltigUndAbgesichertUndPlausibilisiert (QU_AVL_PINA_EPS_SignalwertIstGueltigUndAbgesichertUndPlausibilisiert) (Position ist aufgesetzt und offsetkompensiert. Sensorwert gültig und elektrische Überwachung i.O. und EPS intern plausibilisiert / BNE original name: Signalwert ist gültig und abgesichert und plausibilisiert), 2=SignalwertIstGueltig (QU_AVL_PINA_EPS_SignalwertIstGueltig) (Position ist aufgesetzt und offsetkompensiert Sensorwert gültig und elektrische Überwachung i.O. / BNE original name: Signalwert ist gültig), 4=ErsatzwertIstImNutzsignalGesetzt (QU_AVL_PINA_EPS_ErsatzwertIstImNutzsignalGesetzt) (Signalwert rein aus dem Sensor, d.h. die Position ist aufintegriert (Relativ) Sensorwert gültig und elektrische Überwachung i.O. FUSI: keine Verwendung für sicherheitsrelevante Funktionen. / BNE original name: Ersatzwert ist im Nutzsignal gesetzt), 9=SignalwertIstGueltigZustandSlashStatusTemporaer_mittlereSignalqualitaet_ (QU_AVL_PINA_EPS_SignalwertIstGueltigZustandSlashStatusTemporaer_mittlereSignalqualitaet_) (Wird erst ab SP2015 unterstützt: Position ist aufgesetzt. Die minimale Signaltoleranz ist allerdings noch nicht erreicht. Sensorwert gültig und elektrische Überwachung i.O. / BNE original name: Signalwert ist gültig, Zustand/Status temporär (mittlere Signalqualität)), 10=SignalwertIstGueltigZustandSlashStatusTemporaer_geringeSignalqualitaet_ (QU_AVL_PINA_EPS_SignalwertIstGueltigZustandSlashStatusTemporaer_geringeSignalqualitaet_) (Position ist aufgesetzt, es liegt aber noch eine Signaltoleranz bis etwa 30° Lenkradwinkel vor. Sensorwert gültig und elektrische Überwachung i.O. Wird erst ab SP2013 (außer F15-F16, 444) unterstützt. / BNE original name: Signalwert ist gültig, Zustand/Status temporär (geringe Signalqualität)), 12=AbgleichwertIstImNutzsignalGesetztZustandSlashStatusTemporaer (QU_AVL_PINA_EPS_AbgleichwertIstImNutzsignalGesetztZustandSlashStatusTemporaer) (Nicht vertrauenswürdige aufgesetzte und offsetkompensierte Position, die in diesem Zustand korrigiert wird (durch Aufsetzalgorithmus im ICM). Dieser Zustand bleibt mindestens 50ms bestehen. FUSI: keine Verwendung für sicherheitsrelevante Funktionen. / BNE original name: Abgleichwert ist im Nutzsignal gesetzt, Zustand/Status temporär), 14=SignalwertIstUngueltigZustandSlashStatusTemporaer (QU_AVL_PINA_EPS_SignalwertIstUngueltigZustandSlashStatusTemporaer) (Das zugehörige Nutzsignal wird permanent mit der Ungültigkeitskennung befüllt. Wird gesetzt bei internen EPS Fehler (Sensor Fehler, Interner Kommunikationsfehler,...) Dieser Zustand bleibt mindestens 20ms bestehen. / BNE original name: Signalwert ist ungültig, Zustand/Status temporär), 15=SignalUngueltig (QU_AVL_PINA_EPS_SignalUngueltig) (BNE original name: Signal ungültig)} "Qualifier_Ist_Ritzelwinkel_EPS / Qualifier_actual-value_pinion-angle_EPS"  # Qualifier_Ist_Position_EPS / Qualifier_actual-value_position_EPS | LogicalInterface:BMW.CHASSIS.STEERING.ElectricPowerSteering[internal]@Fahren; Signal Qualifier zum Signal Ist_Position_EPS
          signal UN_PO_EPS: start 62, 2 bit, little-endian, base-type=uint8, invalid-value=value_3Dot0:3, compu {0=Ritzelschnittstelle (UN_PO_EPS_Ritzelschnittstelle) (Die Position wird in Grad übertragen.), 1=Zahnstangenhubschnittstelle (UN_PO_EPS_Zahnstangenhubschnittstelle) (Die Position wird in Millimeter übertragen (Einheit=0.2mm).), 3=SignalUngueltig (UN_PO_EPS_SignalUngueltig) (BNE original name: Signal ungültig)} "Einheit_Position_EPS / unit-of-measurement_position_EPS"  # Einheit_Position_EPS / unit-of-measurement_position_EPS | LogicalInterface:BMW.CHASSIS.STEERING.ElectricPowerSteering[internal]@Fahren; Über dieses Signal wird übermittelt ob die Position als Ritzelwinkel oder Zahnstangenhub zu interpretieren ist. Die Einheit gilt für folgende Signale: - Offset_Zahnstange_Mitte _EPS - Ist_ Position_Index_EPS - Ist_ Position_EPS - Ist_ Position_Index_ICM (im Nachricht Offset Quadrant EPS)
          mapping sigGroup_AVL_PO_EPS: i-signal-group=sigGroup_AVL_PO_EPS
        carries pdu ENGTORQ_EPS: packing-byte-order=little-endian, start-position=64
        pdu ENGTORQ_EPS: length=8, transmission-mode-true-timing=cyclic-timing=time-period={tolerance=absolute-tolerance=0.0, value=0.01}, unused-bit-pattern=255  # Motormoment EPS | Diese PDU enthält Informationen zu Größen aus der EPS
          signal TRGG_ENGTORQ_EPS: start 16, 12 bit, little-endian, base-type=uint16, invalid-value=value_4095Dot0:4095, compu {phys=raw*0.01-10 for raw 1000..201000, 4093=Funktionsschnittstelle_ist_nicht_verfuegbar (TRGG_ENGTORQ_EPS_Funktionsschnittstelle_ist_nicht_verfuegbar) (Sendefunktion in Betrieb, Werte nicht verfügbar), 4094=Funktion_meldet_Fehler (TRGG_ENGTORQ_EPS_Funktion_meldet_Fehler) (Sendefunktion in Betrieb, meldet Fehler), 4095=Signal_unbefuellt (TRGG_ENGTORQ_EPS_Signal_unbefuellt) (Sendefunktion nicht in Betrieb); unit NwtMtr} "Ansteuerung_Motormoment_EPS / triggering_engine-torque_EPS", range phys 0..2000 NwtMtr "Ansteuerung_Motormoment_EPS / triggering_engine-torque_EPS"  # Ansteuerung_Motormoment_EPS / triggering_engine-torque_EPS | LogicalInterface:BMW.CHASSIS.STEERING.ElectricPowerSteering[internal]@Fahren; Das EPS-Soll-Motormoment das an die FOR (Feld Orientierte Regelung) übergeben wird.
      frame SU_CLE_DRDY_DXP_SPEC_ADPT_MOD_DXP_ST_IDLV_COOD_DBE_DXP: to EPS, category=APPLICATION, frame-length=16, flexray-absolutely-scheduled-timing{communication-cycle=cycle-repetition={base-cycle=3, cycle-repetition=CYCLE-REPETITION-8}, slot-id=53}, allow-dynamic-l-sdu-length=false, payload-preamble-indicator=false  # Konfiguration Stellhebel Fahrdynamik Fahrerlebnis / Vorgabe Adaption Modus Fahrerlebnis / Status Individualisierung Koordinator Fahrverhalten Fahrerlebnis | Diese Nachricht setzt sich zusammen aus den PDUs Konfiguration Stellhebel Fahrdynamik Fahrerlebnis, Vorgabe Adaption Modus Fahrerlebnis und Status Individualisierung Koordinator Fahrverhalten Fahrerlebnis.
        pdu SU_CLE_DRDY_DXP: length=8, transmission-mode-true-timing=cyclic-timing=time-period=0.04, unused-bit-pattern=255  # Konfiguration Stellhebel Fahrdynamik Fahrerlebnis | In dieser Botschaft werden die Ausprägungen der teilnehmenden Funktionen des FES Koordinators Fahrverhalten kommuniziert.
          signal FACT_MO_STE_SO_DXP: start 16, 8 bit, little-endian, base-type=uint8, invalid-value=value_255Dot0:255, compu {phys=raw*0.02 for raw 0..12500, 253=Funktionsschnittstelle_ist_nicht_verfuegbar (FACT_MO_STE_SO_DXP_Funktionsschnittstelle_ist_nicht_verfuegbar) (Sendefunktion in Betrieb, Werte nicht verfügbar), 254=Funktion_meldet_Fehler (FACT_MO_STE_SO_DXP_Funktion_meldet_Fehler) (Sendefunktion in Betrieb, meldet Fehler), 255=Signal_unbefuellt (FACT_MO_STE_SO_DXP_Signal_unbefuellt) (Sendefunktion nicht in Betrieb)} "Faktor_Modifikation_Lenkung_Servo_Fahrerlebnis / factor_modification_steering_servo_driving-experience", range phys 0..250 "Faktor_Modifikation_Lenkung_Servo_Fahrerlebnis / factor_modification_steering_servo_driving-experience", to EPS  # Faktor_Modifikation_Lenkung_Servo_Fahrerlebnis / factor_modification_steering_servo_driving-experience | LogicalInterface:BMW.POWERTRAIN.DrivingExperienceControl[internal]@Fahren;
          signal SU_CLU_STMOM_SFE_DXP: start 8, 4 bit, little-endian, base-type=uint8, invalid-value=value_15Dot0:15, compu {1=Ultrahart (SU_CLU_STMOM_SFE_DXP_Ultrahart), 2=SportlichAusgewogen (SU_CLU_STMOM_SFE_DXP_SportlichAusgewogen) (BNE original name: Sportlich ausgewogen), 3=Ausgewogen (SU_CLU_STMOM_SFE_DXP_Ausgewogen), 4=Weich (SU_CLU_STMOM_SFE_DXP_Weich), 13=Funktionsschnittstelle_ist_nicht_verfuegbar (SU_CLU_STMOM_SFE_DXP_Funktionsschnittstelle_ist_nicht_verfuegbar) (Sendefunktion in Betrieb, Werte nicht verfügbar), 14=Funktion_meldet_Fehler (SU_CLU_STMOM_SFE_DXP_Funktion_meldet_Fehler) (Sendefunktion in Betrieb, meldet Fehler), 15=Signal_unbefuellt (SU_CLU_STMOM_SFE_DXP_Signal_unbefuellt) (Sendefunktion nicht in Betrieb)} "Konfiguration_Cluster_Lenkmoment_Lenkgefühl_Fahrerlebnis / setup_cluster_steering-moment_steering-feel_driving-experience", to EPS  # Konfiguration_Cluster_Lenkmoment_Lenkgefühl_Fahrerlebnis / setup_cluster_steering-moment_steering-feel_driving-experience | LogicalInterface:BMW.POWERTRAIN.DrivingExperienceControl[internal]@Fahren; Mit diesem Signal werden die Funktionen des FES Clusters Lenkmoment/Lenkgefühl auf die zum aktuellen FES Modus gehörige Einstellung geschaltet (Lenkunterstützung, Dämpfung, Aktive Rückstellung).
      frame ACLNX_MASSCNTR_ACLNY_MASSCNTR: to EPS, category=APPLICATION, frame-length=14, flexray-absolutely-scheduled-timing{communication-cycle=cycle-repetition={base-cycle=0, cycle-repetition=CYCLE-REPETITION-2}, slot-id=55}, allow-dynamic-l-sdu-length=false, payload-preamble-indicator=false  # Längsbeschleunigung Schwerpunkt / Querbeschleunigung Schwerpunkt | Dieser Frame setzt sich zusammen aus den PDUs Längsbeschleunigung Schwerpunkt und Querbeschleunigung Schwerpunkt.
        carries pdu ACLNY_MASSCNTR: packing-byte-order=little-endian, start-position=64
        pdu ACLNY_MASSCNTR: length=6, transmission-mode-true-timing=cyclic-timing=time-period=0.01, unused-bit-pattern=255  # Querbeschleunigung Schwerpunkt | Gemessene und plausibilisierte Querbeschleunigung im Fahrzeugschwerpunkt. Diese Nachricht wird nicht im EntryHU Gateway der PL7 geroutet.
          signal ACLNY_COG: start 16, 16 bit, little-endian, base-type=uint16, invalid-value=value_65535Dot0:65535, compu {phys=raw*0.002-65 for raw 32500..32532500; unit MtrPerSecSqd} "Codierung zu überarbeiten. Transp.MOST-GW-Migration, 01.09.2006: Zusammenführung der Signalklasse Querbeschleunigung_Schwerpunkt [1] mit den Parametern LateralAccelerationMassCenter [1].", range phys 0..65000 MtrPerSecSqd "Codierung zu überarbeiten. Transp.MOST-GW-Migration, 01.09.2006: Zusammenführung der Signalklasse Querbeschleunigung_Schwerpunkt [1] mit den Parametern LateralAccelerationMassCenter [1].", to EPS  # Querbeschleunigung_Schwerpunkt / lateral-acceleration_centre-of-gravity | LogicalInterface:BMW.POWERTRAIN.SpeedAccelerationDistance[external]@Fahren; Querbeschleunigung im Fahrzeugschwerpunkt. Eine positive Querbeschleunigung wird durch eine vorwärts durchfahrene Linkskurve erzeugt. Fahrzeugkoordinatensystem gemäß ISO 8855. Die Querbeschleunigung des Fahrzeuges wird je nach Fahrzeugkonfiguration von einem oder zwei Querbeschleunigungs-sensoren gemessen. Anschließend erfolgt eine Plausibilisierung (durch Modellüberwachung und Redundanzüberwachung bei zwei Sensoren) und ein Langzeitabgleich der Offset-Drift. Sind zwei Querbeschleunigungssensoren verbaut, so wird der Mittelwert der abgeglichenen Signale als Querbeschleunigungsnutzsignal ausgegeben. Es ist zu beachten, dass dieses Signal die Anteile der Gravitation enthält, die zum Beispiel bei einem wankenden Fzg. oder in einer seitengeneigten Fahrbahn mit gemessen werde. Ist einer von zwei Querbeschleunigungssensoren als fehlerhaft erkannt, so wird der Wert des verbleibenden Sensors als Nutzsignal ausgegeben. Im Qualifier erfolgt die Rückstufung des Signals von "gültig + abgesichert" auf "gültig". Die Einstufung "gültig" gilt entsprechend auch dann, wenn nur ein Querbeschleunigungssensor verbaut und fehlerfrei ist. Sind alle im Fzg. verbauten Querbeschleunigungssensoren als fehlerhaft erkannt, so wird ein Ersatzwert aus den verbleibenden Sensoren im Fzg. (Raddrehzahlen, Lenkwinkel, Querbeschleunigung) berechnet und ausgegeben. Entsprechend erfolgt die Kennzeichnung "Ersatzwert" durch den Qualifier. Transp.MOST-GW-Migration, 01.09.2006: Zusammenführung des Parameters LateralAccelerationMassCenter [1] mit dem Signal Querbeschleunigung_Schwerpunkt [3].
          signal ACLNY_COG_ERR_AMP: start 32, 12 bit, little-endian, base-type=uint16, invalid-value=value_4095Dot0:4095, compu {phys=raw*0.005 for raw 0..800000; unit MtrPerSecSqd}, range phys 0..4000 MtrPerSecSqd, to EPS  # Querbeschleunigung_Schwerpunkt_Fehler_Amplitude / lateral-acceleration_centre-of-gravity_error_amplitude | LogicalInterface:BMW.POWERTRAIN.SpeedAccelerationDistance[external]@Fahren; Für den Fall, dass ein Sensorfehler nicht oder noch nicht erkannt wurde, interne Überwachungsmaßnahmen jedoch anzeigen, dass eine Abweichung des Sensorsignals vom tatsächlichen Wert vorliegen könnte, gibt dieser Wert an, wie groß diese Abweichung maximal sein kann. Es wird der Betrag der Fehleramplitude ausgegeben, die Abweichung des tatsächlichen Signals vom ausgegebenen Signal liegt in einem Band mit der doppelten Breite der Fehleramplitude (Signal plus oder minus Fehleramplitude). Der Qualifier des Nutzsignals behält in diesem Fall seinen bisherigen Wert. Beispiel: zwei nicht als fehlerhaft erkannte Querbeschleunigungssensoren liefern die Werte 4 m/s² und 8 m/s². Das ausgegebene Nutzsignal hat in diesem Fall einen Wert von 6 m/s², die Fehleramplitude einen Wert von 2 m/s².
          signal ACLNY_MASSCNTR_dummy_12_15: start 12, 4 bit, little-endian, init-value=15, base-type=uint8, compu {identical}, range phys 0..15, to EPS
          signal ALIV_ACLNY_COG: start 8, 4 bit, little-endian, base-type=uint8, invalid-value=value_15Dot0:15, compu-method=ALIV_COU_4, to EPS  # Alive_Querbeschleunigung_Schwerpunkt / alive_lateral-acceleration_centre-of-gravity | LogicalInterface:BMW.POWERTRAIN.SpeedAccelerationDistance[external]@Fahren;
          signal CRC_ACLNY_COG: start 0, 8 bit, little-endian, base-type=uint8, compu-method=CRC8, data-constr=CRC8, to EPS  # CRC_Querbeschleunigung_Schwerpunkt / CRC_lateral-acceleration_centre-of-gravity | LogicalInterface:BMW.POWERTRAIN.SpeedAccelerationDistance[external]@Fahren; Standardabsicherung Applikations-CRC Dieses Signal verwendet die Applikations-CRC-ID = 31 (Dez)
          signal QU_ACLNY_COG: start 44, 4 bit, little-endian, base-type=uint8, invalid-value=value_15Dot0:15, compu {8=Initialisierung (QU_ACLNY_COG_Initialisierung) (Tritt während der Initialisierungsphase auf bis Ist-Wert verfügbar (Vorbefüllung). Nutzsignal wird permanent mit Nutzwert 0 befüllt.), 1=SignalwertIstGueltigUndAbgesichertUndPlausibilisiert (QU_ACLNY_COG_SignalwertIstGueltigUndAbgesichertUndPlausibilisiert) (Nutzsignal verfügbar, bereitgestellt aus zwei Sensoren (nur bei redundanter Sensorik) elektrische und Modellüberwachung i.O. / BNE original name: Signalwert ist gültig und abgesichert und plausibilisiert), 9=SignalwertIstGueltigUndAbgesichertZustandSlashStatusTemporaer (QU_ACLNY_COG_SignalwertIstGueltigUndAbgesichertZustandSlashStatusTemporaer) (Nutzsignal verfügbar; elektrische und Modellüberwachung i.O. Es liegt eine Signaltoleranz aufgrund nicht abgeschlossenen Offsetabgleichs an. FuSi : Bei sicherheitsrelevanten Funktionen ist die Fehleramplitude auszuwerten / BNE original name: Signalwert ist gültig und abgesichert, Zustand/Status temporär), 2=SignalwertIstGueltig (QU_ACLNY_COG_SignalwertIstGueltig) (Nutzsignal verfügbar, bereitgestellt aus einem Sensor (Nur bei einfacher Sensorik) elektrische und Modellüberwachung i.O. / BNE original name: Signalwert ist gültig), 10=SignalwertIstGueltigZustandSlashStatusTemporaer (QU_ACLNY_COG_SignalwertIstGueltigZustandSlashStatusTemporaer) (Nutzsignal verfügbar, bereitgestellt aus einem Sensor elektrische und Modellüberwachung i.O. Es liegt eine Signaltoleranz aufgrund nicht abgeschlossenen Offsetabgleichs an. FuSi : Bei sicherheitsrelevanten Funktionen ist die Fehleramplitude auszuwerten / BNE original name: Signalwert ist gültig, Zustand/Status temporär), 3=SignalqualitaetBzwDotUeberwachungEingeschraenkt (QU_ACLNY_COG_SignalqualitaetBzwDotUeberwachungEingeschraenkt) (keine Modellüberwachung, da Eingangsgrößen für Überwachung fehlen (zum Bsp. Gierrate), elektrische Überwachung i.O. Nutzsignal wird aus Sensorwert gebildet. FuSi: keine Verwendung für sicherheitsrelevante Funktionen / BNE original name: Signalqualität bzw. Überwachung eingeschränkt), 11=SignalqualitaetBzwDotUeberwachungEingeschraenktZustandSlashStatusTemporaer (QU_ACLNY_COG_SignalqualitaetBzwDotUeberwachungEingeschraenktZustandSlashStatusTemporaer) (keine Modellüberwachung, da Eingangsgrößen für Überwachung fehlen (zum Bsp. Gierrate), elektrische Überwachung i.O. Es liegt eine Signaltoleranz aufgrund nicht abgeschlossenen Offsetabgleichs an. Nutzsignal wird aus Sensorwert gebildet. FuSi: keine Verwendung für sicherheitsrelevante Funktionen / BNE original name: Signalqualität bzw. Überwachung eingeschränkt, Zustand/Status temporär), 4=Reserved (QU_ACLNY_COG_Reserved), 12=ErsatzwertIstImNutzsignalGesetztZustandSlashStatusTemporaer (QU_ACLNY_COG_ErsatzwertIstImNutzsignalGesetztZustandSlashStatusTemporaer) (elektrische Überwachung oder Modellüberwachung zeigt Fehler an, deshalb wird Ersatzwert aus Modell versendet FuSi: keine Verwendung für sicherheitsrelevante Funktionen / BNE original name: Ersatzwert ist im Nutzsignal gesetzt, Zustand/Status temporär), 6=SignalwertIstUngueltig (QU_ACLNY_COG_SignalwertIstUngueltig) (Das zugehörige Nutzsignal wird permanent mit der Ungültigkeitskennung befüllt. elektrische Überwachung oder Modellüberwachung zeigt Fehler an, kein Ersatzwert verfügbar. Diese Codierung wird ab SP2015 nicht mehr bedient. / BNE original name: Signalwert ist ungültig), 14=SignalwertIstUngueltigZustandSlashStatusTemporaer (QU_ACLNY_COG_SignalwertIstUngueltigZustandSlashStatusTemporaer) (Das zugehörige Nutzsignal wird permanent mit der Ungültigkeitskennung befüllt. elektrische Überwachung oder Modellüberwachung zeigt Fehler an, kein Ersatzwert verfügbar / BNE original name: Signalwert ist ungültig, Zustand/Status temporär), 7=Reserved_bne_18ACE6A1DACA4F44BAB0F4D6BBE8870D_7 (QU_ACLNY_COG_Reserved_bne_18ACE6A1DACA4F44BAB0F4D6BBE8870D_7) (BNE original name: Reserved), 15=SignalUngueltig (QU_ACLNY_COG_SignalUngueltig) (Kann nur vom Gateway gesetzt werden / BNE original name: Signal ungültig)} "Qualifier_Querbeschleunigung_Schwerpunkt / Qualifier_lateral-acceleration_centre-of-gravity", to EPS  # Qualifier_Querbeschleunigung_Schwerpunkt / Qualifier_lateral-acceleration_centre-of-gravity | LogicalInterface:BMW.POWERTRAIN.SpeedAccelerationDistance[external]@Fahren; Erweiterter Status Qualifier zum Signal Querbeschleunigung_Schwerpunkt. Mindestanforderungen um einen gültigen Signalwert senden zu können (Stand 10.06.08 gilt für L6/L7/F25): - Klemme 30B + Geschwindigkeit_Fahrzeug_Schwerpunkt gültig + Lenkwinkel_Vorderachse_effektiv gültig alternative Aufstartbedingung: - Bei Erkennung eines Modellfehlers wird bei Kl.15 Änderung ein Reset durchgeführt. Frühestens 50ms später kann ein gültiger Wert kommen. In dieser Zeit wird der Qualifier auf Initialisierung gesetzt.
          mapping sigGroup_ACLNY_MASSCNTR: i-signal-group=sigGroup_ACLNY_MASSCNTR
      frame V_VEH_V_VEH_2: to EPS, category=APPLICATION, frame-length=16, flexray-absolutely-scheduled-timing{communication-cycle=cycle-repetition={base-cycle=3, cycle-repetition=CYCLE-REPETITION-4}, slot-id=55}, allow-dynamic-l-sdu-length=false, payload-preamble-indicator=false  # Geschwindigkeit Fahrzeug / Geschwindigkeit Fahrzeug 2
        pdu V_VEH: length=5, transmission-mode-true-timing=cyclic-timing=time-period=0.02, unused-bit-pattern=255  # Geschwindigkeit Fahrzeug | Diese Nachricht beinhaltet die Geschwindigkeit des Fahrzeugschwerpunktes und den Fahrzustand des Fahrzeuges.
          signal ALIV_V_VEH: start 8, 4 bit, little-endian, base-type=uint8, invalid-value=value_15Dot0:15, compu {0=Zaehlerstand0DotDotE (ALIV_COU_V_Zaehlerstand0DotDotE) (Nach dem Zählerstand 14 wird zyklisch bei 0 wieder begonnen. / After counter reading 14, the counter restarts at 0 again in cycles / BNE original name: Zählerstand 0..E), 15=SignalUngueltig (ALIV_COU_V_SignalUngueltig) (BNE original name: Signal ungültig)} "Alive_Zähler_Geschwindigkeit / alive_counter_speed | Transp.MOST-GW-Migration, 01.09.2006: Zusammenführung der Signalklasse Alive_Zähler_Geschwindigkeit [1] mit den Parametern AliveSpeed [1].", to EPS  # Alive_Geschwindigkeit_Fahrzeug / alive_speed_vehicle | LogicalInterface:BMW.POWERTRAIN.SpeedAccelerationDistance[external]@Fahren; Transp.MOST-GW-Migration, 01.09.2006: Zusammenführung des Parameters AliveSpeed [1] mit dem Signal Alive_Geschwindigkeit_Fahrzeug [1].
          signal CRC_V_VEH: start 0, 8 bit, little-endian, base-type=uint8, compu {identical} "Standartabsicherung Apllikations-CRC. Transp.MOST-GW-Migration, 01.09.2006: Zusammenführung der Signalklasse CRC_Geschwindigkeit_Fahrzeug [1] mit den Parametern ChecksumSpeedCRC [1].", range phys 0..255 "Standartabsicherung Apllikations-CRC. Transp.MOST-GW-Migration, 01.09.2006: Zusammenführung der Signalklasse CRC_Geschwindigkeit_Fahrzeug [1] mit den Parametern ChecksumSpeedCRC [1].", to EPS  # CRC_Geschwindigkeit_Fahrzeug / CRC_speed_vehicle | LogicalInterface:BMW.POWERTRAIN.SpeedAccelerationDistance[external]@Fahren; Standardabsicherung Applikations-CRC Dieses Signal verwendet die Applikations-CRC-ID = 12 (Dez) Die Checksumme hat keine Ungültigkeitskennung! ACHTUNG: Im Problemfall befüllen Gateways trotzdem immer mit "ungültig" (hier: 0xFF). Transp.MOST-GW-Migration, 01.09.2006: Zusammenführung des Parameters ChecksumSpeedCRC [1] mit dem Signal CRC_Geschwindigkeit_Fahrzeug [2].
          signal DVCO_VEH: start 36, 3 bit, little-endian, base-type=uint8, invalid-value=value_7Dot0:7, compu {0=FahrzeugSteht (DVCO_VEH_FahrzeugSteht) (Siehe Signalbeschreibung / See above / BNE original name: Fahrzeug steht), 1=FahrzeugFaehrtVorwaerts (DVCO_VEH_FahrzeugFaehrtVorwaerts) (VL und VR vorwärts / FL and FR forwards / BNE original name: Fahrzeug fährt vorwärts), 2=FahrzeugFaehrtRueckwaerts (DVCO_VEH_FahrzeugFaehrtRueckwaerts) (VL und VR rückwärts / FL and FR backwards / BNE original name: Fahrzeug fährt rückwärts), 3=FahrzeugFaehrt (DVCO_VEH_FahrzeugFaehrt) (Richtungserkennung noch nicht erfolgt oder nicht möglich z.B. Luftspalt zu groß / Direction recognition not possible, e.g. air gap too large / BNE original name: Fahrzeug fährt), 4=FahrzeugStehtHinterachseAufRollenpruefstandErkannt (DVCO_VEH_FahrzeugStehtHinterachseAufRollenpruefstandErkannt) (Fahrzeug auf Hinterachs-Ein-Achs- Rollenprüfstand erkannt. Signalverhalten von Geschwindigkeit_Fahrzeug_Schwerpunkt siehe Signalbeschreibung DVCO_VEH / BNE original name: Fahrzeug steht, Hinterachse auf Rollenprüfstand erkannt), 5=FahrzeugStehtZwei_Achs_RollenbetriebGesetzt (DVCO_VEH_FahrzeugStehtZwei_Achs_RollenbetriebGesetzt) (Codierung wird beim CAS4 im F25 erst ab I400 richtig interpretiert. Signal Geschwindigkeit_Fahrzeug_Schwerpunkt entspricht der Rollengeschwindigkeit, Details siehe Signalbeschreibung / BNE original name: Fahrzeug steht, Zwei-Achs-Rollenbetrieb gesetzt), 6=FahrzeugStehtVorderachseAufRollenpruefstandErkannt (DVCO_VEH_FahrzeugStehtVorderachseAufRollenpruefstandErkannt) (Fahrzeug auf Vorderachs-Ein-Achs-Rollenprüfstand erkannt. (Bit kann erst ab SP2013 gesetzt werden) Signalverhalten von Geschwindigkeit_Fahrzeug_Schwerpunkt siehe Signalbeschreibung DVCO_VEH / BNE original name: Fahrzeug steht, Vorderachse auf Rollenprüfstand erkannt), 7=SignalUngueltig (DVCO_VEH_SignalUngueltig) (Wird beim Aufstarten gesetzt, solange kein gültiger Zustand ermittelt werden kann und beim Auftreten eines Kommunikationsfehlers. / BNE original name: Signal ungültig)} "Fahrzustand_Fahrzeug / driving-condition_vehicle", to EPS  # Fahrzustand_Fahrzeug / driving-condition_vehicle | LogicalInterface:BMW.POWERTRAIN.SpeedAccelerationDistance[external]@Fahren; Alter Name: Status_Fahrzeug_Fahrzustand. (in L6 immer Sensoren mit Richtungserkennung). Dieses Signal zeigt die Fahrzeugbewegungsrichtung und einen Fahrzeugstillstand an. Fahrzeugstillstand ist gegeben, wenn die ermittelte Fahrzeuggeschwindigkeit kleiner als 0,01 m/s ist. Wenn alle Räder stabil und die Raddrehrichtungen bekannt sind, wird die Fahrtrichtung aus den Raddrehrichtungen bestimmt. Bei instabilen/schlupfbehafteten Rädern oder unbekannten Raddrehrichtungen wird die Fahrtrichtung aus einem Modell aus Längsbeschleunigung und Fahrbahnsteigung bestimmt. In SP2011 und SP2009 (außer PL6) Basisfahrzeugen werden aus Kostengründen Raddrehzahlfühler ohne Drehrichtungserkennung verbaut. Die Fahrtrichtung wird modelbasiert berechnet. Deshalb kann es eine unbestimmte Zeit dauern bis zur Erkennung der Fahrtrichtung (Worst Case erst ab 60km/h) Für bestimmte Sonderaustattungen werden Raddrehzahlfühler mit Drehrichtungserkennung verbaut. In SP2009 und SP2011 gilt für den Rollenbetrieb: Bei Zustand "Fahrzeug steht, Fahrzeug auf Ein-Achs-Rollenprüfstand erkannt" gibt das Signal Geschwindigkeit_Fahrzeug_Schwerpunkt nicht die Rollengeschwindigkeit wieder, sondern kann - bis auf Ausnahme von fremdgetriebenen Rollen mit Geschwindigkeiten bis zu 10km/h (hier wird nie eine Geschwindigkeit größer 10 km/h ausgegeben) - beliebige Werte annehmen. Der Qualifier der Fahrzeuggeschwindigkeit (QU_V_VEH_COG) kann je nach Zustand der Qualifier der Raddrehzahlen (QU_AVL_RPM_WHL_xx) auf den Zustand 1011b (Signalqualität bzw. Überwachung eingeschränkt, Zustand/Status temporär) wechseln. Bedingungen für eine erkannte (Einachs)-Rolle sind (UND-Verknüpfung): - größte Geschwindigkeit an nicht angetriebener Achse sehr klein - kleinste Geschwindigkeit an angetriebener Achse größer Schwelle - Differenzgeschwindigkeit der Räder an der angetriebenen Achse klein - Gierrate klein - Mind. eine Vorderrad- und beide Hinterraddrehzahlen gültig Treffen alle diese Bedingungen durchgehend zu, wird nach einer Zeitdauer von 3,5s im Fahrzustand die erkannte Rolle angezeigt. Bedingungen für das Rücksetzen der Rollenerkennung sind (ODER-Verknüpfung): - grösste Vorderradgeschwindigkeit größer Schwelle - Differenzgeschwindigkeit Hinterräder größer Schwelle - Gierrate grösser Schwelle - Beide Vorderrad- oder eine Hinterraddrehzahl ungültig (1 Zyklus entprellt) Achtung: Die automatische Rollenerkennung ist derzeit nur für Ein-Achs-Rollen möglich. Der Zustand "Fahrzeug steht, Zwei-Achs-Rollenbetrieb" kann im Klemmenzustand KL_30B_EIN aktiv vom Fahrer durch eine entsprechende Tastenkombination im Innenraum gesetzt werden. Dieser Zustand soll den Empfängern des Signals ein energetisch korrektes Verhalten auf der Zwei-Achs-Rolle ermöglichen, z.B. Diagnose Job "Rekuperation bei DSC_OFF" im DSC. Während dieses Zustands gibt das Signal Geschwindigkeit_Fahrzeug_Schwerpunkt nicht die Schwerpunktgeschwindigkeit des Fahrzeugs wieder, sondern es wird (im Gegensatz zur Ein-Achs-Rolle) eine Ersatzgeschwindigkeit aus den gemittelten Hinterachsraddrehzahlen ermittelt, die der Rollengeschwindigkeit entspricht. Der Qualifier QU_V_VEH_COG wird im fehlerfreien Fall auf "0001, Signalwert ist gültig und abgesichert und plausibilisiert" gesetzt. Der Zustand "Fahrzeug steht, Zwei-Achs-Rollenbetrieb" wird zurückgesetzt entweder wenn ein Klemmenwechsel von KL_15N_ein auf KL_15N_aus erfolgt oder wenn eine der folgenden Bedingungen erfüllt ist: - Lenkwinkel überschreitet eine Differenz von 20° (bezogen auf Lenkwinkel bei Setzen des Rollenmodus) - Geschwindigkeit berechnet aus Längsbeschleunigung größer 20 km/h - Gierwinkel größer 3° Ab SP2013 gilt für den Rollenbetrieb: Bei Zustand "Fahrzeug steht, Hinterachse auf Rollenprüfstand erkannt" und "Fahrzeug steht, Vorderachse auf Rollenprüfstand erkannt" gibt das Signal Geschwindigkeit_Fahrzeug_Schwerpunkt die Hinterachs- bzw. Vorderachsgeschwindigkeit und damit die Rollengeschwindigkeit aus. Die Hinterachsgeschwindigkeit wird ebenfalls bei "Fahrzeug steht, Zwei-Achs-Rollenbetrieb gesetzt" ausgegeben. Der Qualifier der Fahrzeuggeschwindigkeit (QU_V_VEH_COG) kann je nach Zustand der Qualifier der Raddrehzahlen (QU_AVL_RPM_WHL_xx) auf den Zustand 1011b (Signalqualität bzw. Überwachung eingeschränkt, Zustand/Status temporär) wechseln. Bedingungen für das Setzen des Rollenbetriebs: - Der Rollenbetrieb muss über eine Kombiroutine initialisiert werden. - Danach ist zunächst die 2-Achsrolle (DVCO_VEH=5) gesetzt. - Steht das Fahrzeug auf einer 1-Achs-Rolle erfolgt die Erkennung automatisch und DVCO_VEH nimmt den entsprechenden Zustand ein. Bedingungen für das Rücksetzen der Rollenerkennung sind (ODER-Verknüpfung): - nicht angetriebene Achsgeschwindigkeit größer Schwelle - Differenzgeschwindigkeit angetriebener Achse größer Schwelle - Gierwinkel grösser Schwelle - ungültige Raddrehzahlen - KL_15N_ein auf KL_15N_aus erfolgt - Lenkwinkel grösser Schwelle - Geschwindigkeit berechnet aus Längsbeschleunigung grösser Schwelle Dieses Signal soll langfristig entfallen und durch die zwei Signale Fahrtrichtung_Fahrzeug_Bestätigt und Status_Rollenmodus ersetzt werden: 1. Komponenten, die nur in 35up und folgenden Baureihen verbaut werden, sollen als Empfänger der neuen Signale Fahrtrichtung_Fahrzeug_Bestätigt und Status_Rollenmodus angetragen werden 2. Komponenten, die in der 35up und rückverbaut werden, sollen weiterhin als Empfänger des alten Signals Fahrzustand_Fahrzeug angetragen werden; zusätzlich können die neuen Signale Fahrtrichtung_Fahrzeug_Bestätigt und Status_Rollenmodus empfangen werden. 3. Bestandskomponenten werden mit dem alten Signal beliefert solange sie verbaut werden. 4. Nach Auslauf der letzten Bestandskomponenten soll das Signals Fahrzustand_Fahrzeug entfallen 5. Wird eine Komponente aus anderen Gründen geändert, wird empfohlen auf die neuen Signale umzustellen mit dem Ziel eines früheren Entfalls des Signals Fahrzustand_Fahrzeug
          signal QU_V_VEH_COG: start 32, 4 bit, little-endian, base-type=uint8, invalid-value=value_15Dot0:15, compu {8=Initialisierung (QU_V_VEH_COG_Initialisierung) (Tritt während der Initialisierungsphase auf bis Ist-Wert verfügbar (Vorbefüllung). Nutzsignal wird permanent mit Nutzwert 0 befüllt.), 1=SignalwertIstGueltigUndAbgesichertUndPlausibilisiert (QU_V_VEH_COG_SignalwertIstGueltigUndAbgesichertUndPlausibilisiert) (BNE original name: Signalwert ist gültig und abgesichert und plausibilisiert), 9=Reserved (QU_V_VEH_COG_Reserved), 2=Reserved_bne_C9CB853E97D84E34ADF2107B01966081_2 (QU_V_VEH_COG_Reserved_bne_C9CB853E97D84E34ADF2107B01966081_2) (BNE original name: Reserved), 10=SignalwertIstGueltigZustandSlashStatusTemporaer (QU_V_VEH_COG_SignalwertIstGueltigZustandSlashStatusTemporaer) (FUSI: Eine für die Berechnung der Geschwindigkeit notwendige Größe fehlt (z.B. Längsbeschleunigung, Raddrehzahl,...). Signalqualität bei instabiler Fahrt eingeschränkt. (Für sicherheitsrelevante Funktionen Anwendbarkeit des Signals prüfen.) / BNE original name: Signalwert ist gültig, Zustand/Status temporär), 3=Reserved_bne_C9CB853E97D84E34ADF2107B01966081_3 (QU_V_VEH_COG_Reserved_bne_C9CB853E97D84E34ADF2107B01966081_3) (BNE original name: Reserved), 11=SignalqualitaetBzwDotUeberwachungEingeschraenktZustandSlashStatusTemporaer (QU_V_VEH_COG_SignalqualitaetBzwDotUeberwachungEingeschraenktZustandSlashStatusTemporaer) (FUSI: Mehr als eine für die Berechnung der Geschwindigkeit notwendige Größe fehlt (z.B. Längsbeschleunigung, Raddrehzahl,...). Signalqualität bei instabiler Fahrt eingeschränkt. (Für sicherheitsrelevante Funktionen Anwendbarkeit des Signals prüfen.) / BNE original name: Signalqualität bzw. Überwachung eingeschränkt, Zustand/Status temporär), 4=Reserved_bne_C9CB853E97D84E34ADF2107B01966081_4 (QU_V_VEH_COG_Reserved_bne_C9CB853E97D84E34ADF2107B01966081_4) (BNE original name: Reserved), 12=Reserved_bne_C9CB853E97D84E34ADF2107B01966081_12 (QU_V_VEH_COG_Reserved_bne_C9CB853E97D84E34ADF2107B01966081_12) (BNE original name: Reserved), 6=Reserved_bne_C9CB853E97D84E34ADF2107B01966081_6 (QU_V_VEH_COG_Reserved_bne_C9CB853E97D84E34ADF2107B01966081_6) (BNE original name: Reserved), 14=SignalwertIstUngueltigZustandSlashStatusTemporaer (QU_V_VEH_COG_SignalwertIstUngueltigZustandSlashStatusTemporaer) (Keine Raddrehzahlen verfügbar, Berechnung der Geschwindigkeit nicht möglich. Das zugehörige Nutzsignal wird permanent mit der Ungültigkeitskennung befüllt. / BNE original name: Signalwert ist ungültig, Zustand/Status temporär), 7=Reserved_bne_C9CB853E97D84E34ADF2107B01966081_7 (QU_V_VEH_COG_Reserved_bne_C9CB853E97D84E34ADF2107B01966081_7) (BNE original name: Reserved), 15=SignalUngueltig (QU_V_VEH_COG_SignalUngueltig) (Kann nur vom Gateway gesetzt werden / BNE original name: Signal ungültig)} "Qualifier_Geschwindigkeit_Fahrzeug_Schwerpunkt / Qualifier_speed_vehicle_centre-of-gravity", to EPS  # Qualifier_Geschwindigkeit_Fahrzeug_Schwerpunkt / Qualifier_speed_vehicle_centre-of-gravity | LogicalInterface:BMW.POWERTRAIN.SpeedAccelerationDistance[external]@Fahren; Status Qualifier zum Signal Geschwindigkeit_Fahrzeug_Schwerpunkt. Mindestanforderungen um einen gültigen Signalwert senden zu können (Stand 10.06.08 gilt für L6/L7/F25): - Klemme 30B + mind. drei Ist_Drehzahl_Rad_xx gültig + Lenkwinkel_Vorderachse_effektiv gültig (im F25/L7 erst ab Kl.15N) "Ursprünglich wurden alle reservierten Zustände des Qualifier definiert (nach dem Qualifier-Standard). Beim Kombi wurden diese Zustände dementsprechend in der Software berücksichtigt. Die jetzt mit "reserviert" gekennzeichneten Zustände wurden aber seitens Sender nie befüllt. Das Kombi wertet die mit "reserviert" gekennzeichneten Zustände wie ursprünglich definiert weiterhin aus."
          signal ST_V_VEH_NSS: start 12, 4 bit, little-endian, base-type=uint8, invalid-value=value_15Dot0:15, compu {12=FahrzeugImStillstandsnahenBereich (ST_V_VEH_NSS_FahrzeugImStillstandsnahenBereich) (Dieser Zustand wird eingenommen wenn sowohl die Fahrzeuggeschwindigkeit (V_VEH_COG) als auch die 4 Einzelradgeschwindigkeit 10 kmh unterschreiten. / BNE original name: Fahrzeug im stillstandsnahen Bereich), 13=FahrzeugNichtImStillstandsnahenBereich (ST_V_VEH_NSS_FahrzeugNichtImStillstandsnahenBereich) (Dieser Zustand wird eingenommen wenn das Fahrzeug sich nicht sicher im stillstandsnahen Bereich befindet. Mindestens eine der 5 Geschwindigkeiten, Fahrzeuggeschwindigkeit (V_VEH_COG) oder Einzelradgeschwindigkeiten, überschreitet die Schwelle von 10 kmh. Das heißt das Fahrzeug kann eine beliebige Geschwindigkeit aufweisen, auch unter 10 kmh. Es bedeutet nicht zwangsläufig dass das Fahrzeug schneller als 10kmh fährt. / BNE original name: Fahrzeug nicht im stillstandsnahen Bereich), 15=SignalUngueltig (ST_V_VEH_NSS_SignalUngueltig) (Dieser Zustand wird beim Aufstarten des Steuergeräts gesetzt bis ein gültiger Wert bereit gestellt werden kann. Während des laufenden Betriebs kann dieser Zustand eingenommen werden, wenn die Raddrehzahlen nicht zur Verfügung stehen. / BNE original name: Signal ungültig)} "Status_Geschwindigkeit_Fahrzeug_Stillstandsnah / status_speed_vehicle_near-standstill", to EPS  # Status_Geschwindigkeit_Fahrzeug_Stillstandsnah / status_speed_vehicle_near-standstill | LogicalInterface:BMW.POWERTRAIN.SpeedAccelerationDistance[external]@Fahren; Dieses Signal zeigt an, ob sich das Fahrzeug im stillstandsnahen Bereich (kleiner 10 km/h) befindet. Dazu müssen alle vier Drehzahlfühler (AVL_RPM_WHL_xxH) und die Referenzgeschwindigkeit V_VEH_COG einen Geschwindigkeitswert kleiner 10 km/h aufweisen.
          signal V_VEH_COG: start 16, 16 bit, little-endian, base-type=uint16, invalid-value=value_65535Dot0:65535, compu {phys=raw/64 for raw 0..1433600; unit kilometer_per_hour} "Transp.MOST-GW-Migration, 01.09.2006: Zusammenführung der Signalklasse Geschwindigkeit_Fahrzeug_Schwerpunkt [2] mit den Parametern CarSpeedExt [1].", range phys 0..22400 kilometer_per_hour "Transp.MOST-GW-Migration, 01.09.2006: Zusammenführung der Signalklasse Geschwindigkeit_Fahrzeug_Schwerpunkt [2] mit den Parametern CarSpeedExt [1].", to EPS  # Geschwindigkeit_Fahrzeug_Schwerpunkt / speed_vehicle_centre-of-gravity | LogicalInterface:BMW.POWERTRAIN.SpeedAccelerationDistance[external]@Fahren; Absolutgeschwindigkeit des Fahrzeugschwerpunktes, enthält die Anteile aus Fahrzeuglängs- und Quergeschwindigkeit. Dieses Signal beruht im Wesentlichen auf den vier Raddrehzahlen. Dazu erfolgt die Berechnung und Plausibilisierung der Schwerpunktsgeschwindigkeit. In Fällen, in denen die Raddrehzahlen nur eine ungenaue Aussage über die Fzg.-Geschwindigkeit liefern (großer Schlupf an vier Rädern), erfolgt eine Stützung des Signals über Modellgrößen und weitere Sensorik (z. Bsp. Längsbeschleunigungssensor). Die Geschwindigkeit kann nur positive Werte annehmen, die Fahrtrichtung wird durch das Signal "Fahrzustand_Fahrzeug" angezeigt. Bei Ausfall von einem bis drei Raddrehzahlsensoren erfolgt die Berechnung über die restlichen verfügbaren Sensoren. Die schlechtere Signalqualität wird durch den Qualifier "Wert nicht vertrauenswürdig" gekennzeichnet. Bei Ausfall aller vier Raddrehzahlsensoren kann kein auf einem Modell oder zusätzlicher Sensorik beruhender Ersatzwert ausgegeben werden, daher wird in diesem Fall der Wert Null ausgegeben und der Qualifier auf "Signalwert ist ungültig" gesetzt. Transp.MOST-GW-Migration, 01.09.2006: Zusammenführung des Parameters CarSpeedExt [1] mit dem Signal Geschwindigkeit_Fahrzeug_Schwerpunkt [2].
          signal V_VEH_dummy_39_39: start 39, 1 bit, little-endian, init-value=1, base-type=uint8, compu {identical}, range phys 0..1, to EPS
          mapping sigGroup_V_VEH: i-signal-group=sigGroup_V_VEH
      frame DT_DRDYSEN_EXT_VYAW_VEH: to EPS, category=APPLICATION, frame-length=14, flexray-absolutely-scheduled-timing{communication-cycle=cycle-repetition={base-cycle=0, cycle-repetition=CYCLE-REPETITION-2}, slot-id=56}, allow-dynamic-l-sdu-length=false, payload-preamble-indicator=false  # Daten Fahrdynamiksensor Erweitert / Giergeschwindigkeit Fahrzeug
        carries pdu VYAW_VEH: packing-byte-order=little-endian, start-position=64
        pdu VYAW_VEH: length=6, transmission-mode-true-timing=cyclic-timing=time-period=0.01, unused-bit-pattern=255  # Giergeschwindigkeit Fahrzeug | Gemessene und plausibilisierte Giergeschwindigkeit des Fahrzeugs. Diese Nachricht wird nicht im EntryHU Gateway der PL7 geroutet.
          signal ALIV_VYAW_VEH: start 8, 4 bit, little-endian, base-type=uint8, invalid-value=value_15Dot0:15, compu-method=ALIV_COU_4, to EPS  # Alive_Giergeschwindigkeit_Fahrzeug / alive_yaw-velocity_vehicle | LogicalInterface:BMW.POWERTRAIN.SpeedAccelerationDistance[external]@Fahren;
          signal CRC_VYAW_VEH: start 0, 8 bit, little-endian, base-type=uint8, compu-method=CRC8, data-constr=CRC8, to EPS  # CRC_Giergeschwindigkeit_Fahrzeug / CRC_yaw-velocity_vehicle | LogicalInterface:BMW.POWERTRAIN.SpeedAccelerationDistance[external]@Fahren; Standardabsicherung Applikations-CRC Dieses Signal verwendet die Applikations-CRC-ID = 14 (Dez)
          signal QU_VYAW_VEH: start 44, 4 bit, little-endian, base-type=uint8, invalid-value=value_15Dot0:15, compu {8=Initialisierung (QU_VYAW_VEH_Initialisierung) (Tritt während der Initialisierungsphase auf bis Ist-Wert verfügbar (Vorbefüllung). Nutzsignal wird permanent mit Nutzwert 0 befüllt.), 1=SignalwertIstGueltigUndAbgesichertUndPlausibilisiert (QU_VYAW_VEH_SignalwertIstGueltigUndAbgesichertUndPlausibilisiert) (Nutzsignal verfügbar, bereitgestellt aus zwei Sensoren (nur bei redundanter Sensorik) elektrische und Modellüberwachung i.O. / BNE original name: Signalwert ist gültig und abgesichert und plausibilisiert), 9=SignalwertIstGueltigUndAbgesichertZustandSlashStatusTemporaer (QU_VYAW_VEH_SignalwertIstGueltigUndAbgesichertZustandSlashStatusTemporaer) (Nutzsignal verfügbar, bereitgestellt aus zwei Sensoren (nur bei redundanter Sensorik) elektrische und Modellüberwachung i.O. Es liegt eine Signaltoleranz aufgrund nicht abgeschlossenen Offsetabgleichs an. FuSi : Bei sicherheitsrelevanten Funktionen ist die Fehleramplitude auszuwerten / BNE original name: Signalwert ist gültig und abgesichert, Zustand/Status temporär), 2=SignalwertIstGueltig (QU_VYAW_VEH_SignalwertIstGueltig) (Nutzsignal verfügbar, bereitgestellt aus einem Sensor elektrische und Modellüberwachung i.O. / BNE original name: Signalwert ist gültig), 10=SignalwertIstGueltigZustandSlashStatusTemporaer (QU_VYAW_VEH_SignalwertIstGueltigZustandSlashStatusTemporaer) (Nutzsignal verfügbar, bereitgestellt aus einem Sensor elektrische und Modellüberwachung i.O. Es liegt eine Signaltoleranz aufgrund nicht abgeschlossenen Offsetabgleichs an. FuSi : Bei sicherheitsrelevanten Funktionen ist die Fehleramplitude auszuwerten. / BNE original name: Signalwert ist gültig, Zustand/Status temporär), 3=SignalqualitaetBzwDotUeberwachungEingeschraenkt (QU_VYAW_VEH_SignalqualitaetBzwDotUeberwachungEingeschraenkt) (keine Modellüberwachung, da Eingangsgrößen für Überwachung fehlen (zum Bsp. Querbeschleunigung, Lenkwinkel, ...), elektrische Überwachung i.O Nutzsignal wird aus Sensorwert gebildet. FuSi: keine Verwendung für sicherheitsrelevante Funktionen / BNE original name: Signalqualität bzw. Überwachung eingeschränkt), 11=SignalqualitaetBzwDotUeberwachungEingeschraenktZustandSlashStatusTemporaer (QU_VYAW_VEH_SignalqualitaetBzwDotUeberwachungEingeschraenktZustandSlashStatusTemporaer) (keine Modellüberwachung, da Eingangsgrößen für Überwachung fehlen (zum Bsp. Querbeschleunigung, Lenkwinkel, ...), elektrische Überwachung i.O Es liegt eine Signaltoleranz aufgrund nicht abgeschlossenen Offsetabgleichs an. Nutzsignal wird aus Sensorwert gebildet. FuSi : Bei sicherheitsrelevanten Funktionen ist die Fehleramplitude auszuwerten / BNE original name: Signalqualität bzw. Überwachung eingeschränkt, Zustand/Status temporär), 4=Reserved (QU_VYAW_VEH_Reserved), 12=ErsatzwertColonAbgleichwertIstImNutzsignalGesetztZustandSlashStatusTemporaer (QU_VYAW_VEH_ErsatzwertColonAbgleichwertIstImNutzsignalGesetztZustandSlashStatusTemporaer) (elektrische Überwachung oder Modellüberwachung zeigt Fehler an, deshalb wird Ersatzwert aus Modell (Lenkwinkel) versendet FuSi: keine Verwendung für sicherheitsrelevante Funktionen / BNE original name: Ersatzwert: Abgleichwert ist im Nutzsignal gesetzt, Zustand/Status temporär), 6=SignalwertIstUngueltig (QU_VYAW_VEH_SignalwertIstUngueltig) (elektrische Überwachung oder Modellüberwachung zeigt Fehler an, kein Ersatzwert verfügbar (Steuergerät interner Fehler). Das zugehörige Nutzsignal wird permanent mit der Ungültigkeitskennung befüllt. Diese Codierung wird ab SP2015 nicht mehr bedient. / BNE original name: Signalwert ist ungültig), 14=SignalwertIstUngueltigZustandSlashStatusTemporaer (QU_VYAW_VEH_SignalwertIstUngueltigZustandSlashStatusTemporaer) (elektrische Überwachung oder Modellüberwachung zeigt Fehler an, kein Ersatzwert verfügbar (Eingangssignale Fehler). Das zugehörige Nutzsignal wird permanent mit der Ungültigkeitskennung befüllt. / BNE original name: Signalwert ist ungültig, Zustand/Status temporär), 7=Reserved_bne_7C322122A3AD4C1BBA9012320D4729F1_7 (QU_VYAW_VEH_Reserved_bne_7C322122A3AD4C1BBA9012320D4729F1_7) (BNE original name: Reserved), 15=SignalUngueltig (QU_VYAW_VEH_SignalUngueltig) (Kann nur vom Gateway gesetzt werden / BNE original name: Signal ungültig)} "Qualifier_Giergeschwindigkeit_Fahrzeug / Qualifier_yaw-velocity_vehicle", to EPS  # Qualifier_Giergeschwindigkeit_Fahrzeug / Qualifier_yaw-velocity_vehicle | LogicalInterface:BMW.POWERTRAIN.SpeedAccelerationDistance[external]@Fahren; Erweiterter Status Qualifier zum Signal Giergeschwindigkeit_Fahrzeug. Mindestanforderungen um einen gültigen Signalwert senden zu können (Stand 10.06.08 gilt für L6/L7/F25): - Klemme 30B + Geschwindigkeit_Fahrzeug_Schwerpunkt gültig + Lenkwinkel_Vorderachse_effektiv gültig alternative Aufstartbedingung: - Bei Erkennung eines Modellfehlers wird bei Kl.15 Änderung ein Reset durchgeführt. Frühestens 50ms später kann ein gültiger Wert kommen. In dieser Zeit wird der Qualifier auf Initialisierung gesetzt. Ab der F010-10-01-350 gibt es baureihenübergreifend folgende Spezifikationsänderung: Wenn der Gierratensensor im Anschlag ist (z. Bsp. bei der Rückwärtsschleuderwende), wird nicht wie bisher auf VYAW_VEH ein Ersatzwert und im Qualifier die Codierung 12 (dec) gesendet, sondern es wird der begrenzte Wert ausgegeben und der Qualifier bleibt auf gültig.
          signal VYAW_VEH: start 16, 16 bit, little-endian, base-type=uint16, invalid-value=value_65535Dot0:65535, compu {phys=raw*0.005-163.84 for raw 32768..13139567.999999998; unit degree_per_second} "Transp.MOST-GW-Migration, 01.09.2006: Zusammenführung der Signalklasse Giergeschwindigkeit_Fahrzeug [1] mit den Parametern YawVelocityVehicle [1].", range phys 0..65534 degree_per_second "Transp.MOST-GW-Migration, 01.09.2006: Zusammenführung der Signalklasse Giergeschwindigkeit_Fahrzeug [1] mit den Parametern YawVelocityVehicle [1].", to EPS  # Giergeschwindigkeit_Fahrzeug / yaw-velocity_vehicle | LogicalInterface:BMW.POWERTRAIN.SpeedAccelerationDistance[external]@Fahren; Giergeschwindigkeit des Fahrzeugs. Richtung nach ISO 8855 (positiver Winkel entspricht Drehung gegen den Uhrzeigersinn). Die Giergeschwindigkeit des Fahrzeuges wird je nach Fahrzeugkonfiguration von einem oder zwei Gierratensensoren gemessen. Es erfolgt eine Plausibilisierung (durch Modellüberwachung, Gradientenüberwachung und Redundanzüberwachung bei zwei Sensoren) und ein Langzeitabgleich der Offset-Drifts. Sind zwei Gierratensensoren verbaut, so wird der Mittelwert der abgeglichenen Signale als Gierratennutzsignal ausgegeben. Ist einer von zwei Gierratensensoren als fehlerhaft erkannt, so wird der Wert des verbleibenden Sensors als Nutzsignal ausgegeben. Im Qualifier erfolgt die Rückstufung des Signals von "gültig + abgesichert" auf "gültig". Die Einstufung "gültig" gilt entsprechend auch dann, wenn nur ein Gierratensensor verbaut und fehlerfrei ist. Sind alle im Fzg. verbauten Gierratensensoren als fehlerhaft erkannt, so wird ein Ersatzwert aus den verbleibenden Sensoren im Fzg. (Raddrehzahlen, Lenkwinkel, Querbeschleunigung) berechnet und ausgegeben. Entsprechend erfolgt die Kennzeichnung "Ersatzwert" durch den Qualifier. Transp.MOST-GW-Migration, 01.09.2006: Zusammenführung des Parameters YawVelocityVehicle [1] mit dem Signal Giergeschwindigkeit_Fahrzeug [3].
          signal VYAW_VEH_ERR_AMP: start 32, 12 bit, little-endian, base-type=uint16, invalid-value=value_4095Dot0:4095, compu {phys=raw*0.0125 for raw 0..320000; unit degree_per_second} "Quantisierung ist temporär", range phys 0..4000 degree_per_second "Quantisierung ist temporär", to EPS  # Giergeschwindigkeit_Fahrzeug_Fehler_Amplitude / yaw-velocity_vehicle_error_amplitude | LogicalInterface:BMW.POWERTRAIN.SpeedAccelerationDistance[external]@Fahren; Für den Fall, dass ein Sensorfehler nicht oder noch nicht erkannt wurde, interne Überwachungsmaßnahmen jedoch anzeigen, dass eine Abweichung des Sensorsignals vom tatsächlichen Wert vorliegen könnte, gibt dieser Wert an, wie groß diese Abweichung maximal sein kann. Es wird der Betrag der Fehleramplitude ausgegeben, die Abweichung des tatsächlichen Signals vom ausgegebenen Signal liegt in einem Band mit der doppelten Breite der Fehleramplitude (Signal plus oder minus Fehleramplitude). Der Qualifier des Nutzsignals behält in diesem Fall seinen bisherigen Wert. Beispiel: zwei nicht als fehlerhaft erkannte Gierratensensoren liefern die Werte 10°/s und 20°/s. Das ausgegebene Nutzsignal hat in diesem Fall einen Wert von 15°/s, die Fehleramplitude einen Wert von 5°/s.
          signal VYAW_VEH_dummy_12_15: start 12, 4 bit, little-endian, init-value=15, base-type=uint8, compu {identical}, range phys 0..15, to EPS
          mapping sigGroup_VYAW_VEH: i-signal-group=sigGroup_VYAW_VEH
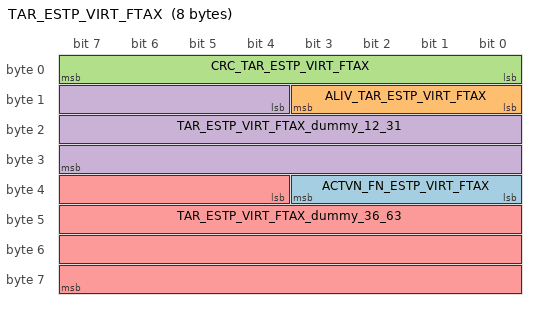
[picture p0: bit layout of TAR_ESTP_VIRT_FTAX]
      frame TAR_ESTP_VIRT_FTAX: to EPS, category=APPLICATION, frame-length=8, flexray-absolutely-scheduled-timing{communication-cycle=cycle-repetition={base-cycle=1, cycle-repetition=CYCLE-REPETITION-2}, slot-id=65}, allow-dynamic-l-sdu-length=false, payload-preamble-indicator=false  # Soll Endanschlag Virtuell Vorderachse
        pdu TAR_ESTP_VIRT_FTAX: length=8, transmission-mode-true-timing=cyclic-timing=time-period=0.01, unused-bit-pattern=255  # Soll Endanschlag Virtuell Vorderachse
          signal ACTVN_FN_ESTP_VIRT_FTAX: start 32, 4 bit, little-endian, base-type=uint8, invalid-value=value_15Dot0:15, compu {0=FunktionVirtuellerEndanschlagDeaktivieren (ACTVN_FN_ESTP_VIRT_FTAX_FunktionVirtuellerEndanschlagDeaktivieren) (Funktion virtueller Endanschlag deaktivieren durch Fahrzeugführung / BNE original name: Funktion virtueller Endanschlag deaktivieren), 1=FunktionVirtuellerEndanschlagAktivieren (ACTVN_FN_ESTP_VIRT_FTAX_FunktionVirtuellerEndanschlagAktivieren) (Funktion virtueller Endanschlag aktivieren durch Fahrzeugführung / BNE original name: Funktion virtueller Endanschlag aktivieren), 13=Funktionsschnittstelle_ist_nicht_verfuegbar (ACTVN_FN_ESTP_VIRT_FTAX_Funktionsschnittstelle_ist_nicht_verfuegbar) (Sendefunktion in Betrieb, Werte nicht verfügbar), 14=Funktion_meldet_Fehler (ACTVN_FN_ESTP_VIRT_FTAX_Funktion_meldet_Fehler) (Sendefunktion in Betrieb, meldet Fehler), 15=Signal_unbefuellt (ACTVN_FN_ESTP_VIRT_FTAX_Signal_unbefuellt) (Sendefunktion nicht in Betrieb)} "Aktivierung_Funktion_Endanschlag_Virtuell_Vorderachse / activation_function_end-stop_virtual_front-axle", to EPS  # Aktivierung_Funktion_Endanschlag_Virtuell_Vorderachse / activation_function_end-stop_virtual_front-axle | LogicalInterface:BMW.CHASSIS.STEERING.SteeringAngle[internal]@Fahren; Dieses Signal gibt an, ob der virtuelle Endanschlag der EPS aktiviert bzw. deaktiviert werden soll.
          signal ALIV_TAR_ESTP_VIRT_FTAX: start 8, 4 bit, little-endian, base-type=uint8, invalid-value=value_15Dot0:15, compu {identical}, range phys 0..14, to EPS  # Alive_Soll_Endanschlag_Virtuell_Vorderachse / alive_target_end-stop_virtual_front-axle | LogicalInterface:BMW.CHASSIS.STEERING.SteeringAngle[internal]@Fahren; Standardabsicherung Alivezähler laut Definition per Lastenheft Allgemeine Bordnetzkommunikation Dieses Signal soll nur überwacht werden, wenn Aktivlenkung und ein Lenksäulensteller verbaut sind.
          signal CRC_TAR_ESTP_VIRT_FTAX: start 0, 8 bit, little-endian, base-type=uint8, compu-method=CRC8, data-constr=CRC8, to EPS  # CRC_Soll_Endanschlag_Virtuell_Vorderachse / CRC_target_end-stop_virtual_front-axle | LogicalInterface:BMW.CHASSIS.STEERING.SteeringAngle[internal]@Fahren; Dieses Signal verwendet die Applikations-CRC-ID = 52 (Dez) Dieses Signal soll nur überwacht werden, wenn Aktivlenkung und ein Lenksäulensteller verbaut sind.
          signal TAR_ESTP_VIRT_FTAX_dummy_12_31: start 12, 20 bit, little-endian, init-value=1048575, base-type=uint32, compu {identical}, range phys 0..1048575, to EPS
          signal TAR_ESTP_VIRT_FTAX_dummy_36_63: start 36, 28 bit, little-endian, init-value=268435455, base-type=uint32, compu {identical}, range phys 0..268435455, to EPS
          mapping sigGroup_TAR_ESTP_VIRT_FTAX: i-signal-group=sigGroup_TAR_ESTP_VIRT_FTAX
      frame TAR_QTA_STRMOM_DV_TAR_STMOM_DV_ACT: to EPS, category=APPLICATION, frame-length=16, flexray-absolutely-scheduled-timing{communication-cycle=cycle-repetition={base-cycle=0, cycle-repetition=CYCLE-REPETITION-2}, slot-id=68}, allow-dynamic-l-sdu-length=false, payload-preamble-indicator=false  # Soll Anteil Lenkmoment Fahrer / Soll Lenkmoment Fahrer Stellglied / target quota steering-moment driver / Soll Lenkmoment Fahrer Stellglied | Soll-Offset-Handmoment.
        pdu TAR_QTA_STRMOM_DV: length=8, transmission-mode-true-timing=cyclic-timing=time-period=0.01, unused-bit-pattern=255  # Soll Anteil Lenkmoment Fahrer / target quota steering-moment Fahrer | Diese Nachricht wird nur bei Fahrzeugen mit elektrischer Lenkung unterstützt. Soll-Offset-Handmoment
          signal ALIV_TAR_QTA_STMOM_DV: start 8, 4 bit, little-endian, base-type=uint8, invalid-value=value_15Dot0:15, compu-method=ALIV_COU_4, to EPS  # Alive_Soll_Anteil_Lenkmoment_Fahrer / alive_target_quota_steering-moment_driver | LogicalInterface:BMW.CHASSIS.STEERING.SteeringAngle[internal]@Fahren; Standardabsicherung Alivezähler laut Definition per Lastenheft Allgemeine Bordnetzkommunikation.
          signal CRC_TAR_QTA_STMOM_DV: start 0, 8 bit, little-endian, base-type=uint8, compu-method=CRC8, data-constr=CRC8, to EPS  # CRC_Soll_Anteil_Lenkmoment_Fahrer / CRC_target_quota_steering-moment_driver | LogicalInterface:BMW.CHASSIS.STEERING.SteeringAngle[internal]@Fahren; Standardabsicherung Applikations-CRC laut Definition per Lastenheft Allgemeine Bordnetzkommunikation. Dieses Signal verwendet die Applikations-CRC-ID = 109 (Dez)
          signal CTR_DEAC_EPS_FNS: start 60, 4 bit, little-endian, base-type=uint8, invalid-value=value_15Dot0:15, compu {mask 15: 0=Keine_Deaktivierung_EPS_Funktionen (CTR_DEAC_EPS_FNS_Keine_Deaktivierung_EPS_Funktionen) (Es besteht keine Anforderung zur Deaktivierung von Funktionen auf der EPS.), mask 15: 13=Funktionsschnittstelle_ist_nicht_verfuegbar (CTR_DEAC_EPS_FNS_Funktionsschnittstelle_ist_nicht_verfuegbar) (Sendefunktion in Betrieb, Werte nicht verfügbar), mask 15: 14=Funktion_meldet_Fehler (CTR_DEAC_EPS_FNS_Funktion_meldet_Fehler) (Sendefunktion in Betrieb, meldet Fehler), mask 15: 15=Signal_unbefuellt (CTR_DEAC_EPS_FNS_Signal_unbefuellt) (Wird nicht aktiv gesetzt), mask 9: 1=Deaktivierung_EPS_Funktionen_Funktionsgruppe_1 (CTR_DEAC_EPS_FNS_Deaktivierung_EPS_Funktionen_Funktionsgruppe_1) (Anforderung zur Deaktivierung einer spezifizierten Funktionsgruppe 1 auf der EPS. Die detaillierte Spezifikation der Funktionsgruppe 1 erfolgt im Entwicklungsprozess mit den Lieferanten. / BNE original name: Deaktivierung_EPS_Funktionen_ Funktionsgruppe_1), mask 10: 2=Deaktivierung_EPS_Funktionen_Funktionsgruppe_2 (CTR_DEAC_EPS_FNS_Deaktivierung_EPS_Funktionen_Funktionsgruppe_2) (Anforderung zur Deaktivierung einer spezifizierten Funktionsgruppe 2 auf der EPS. Die detaillierte Spezifikation der Funktionsgruppe 2 erfolgt im Entwicklungsprozess mit den Lieferanten. / BNE original name: Deaktivierung_EPS_Funktionen_ Funktionsgruppe_2)} "Steuerung_Deaktivierung_EPS_Funktionen / control_deactivation_EPS_functions", to EPS  # Steuerung_Deaktivierung_EPS_Funktionen / control_deactivation_EPS_functions | LogicalInterface:BMW.CHASSIS.STEERING.SteeringAngle[internal]@Fahren; Dieses Signal beinhaltet die Information zur Deaktivierung einzelner Funktionen auf der EPS.
          signal FACT_ASS_STMOM_FTAX: start 48, 8 bit, little-endian, base-type=uint8, invalid-value=value_255Dot0:255, compu {phys=raw/256+1 for raw -256..64768}, range phys 0..254, to EPS  # Faktor_Unterstützung_Lenkmoment_Vorderachse / factor_assistance_steering-moment_front-axle | LogicalInterface:BMW.CHASSIS.STEERING.SteeringAngle[internal]@Fahren; Dieser Faktor wird als Multiplikator für den Steuerung der Lenkunterstützungsberechnung benötigt. Vollständige Quantisierung/Offsetsangabe: (PH) = 0.00390625 * (HEX) + 1
          signal FACT_CTRR_STMOM_FTAX: start 32, 8 bit, little-endian, base-type=uint8, invalid-value=value_255Dot0:255, compu {phys=raw/256+0.0078125 for raw -2..65022}, range phys 0..254, to EPS  # Faktor_Zentrierung_Lenkmoment_Vorderachse / factor_centering_steering-moment_front-axle | LogicalInterface:BMW.CHASSIS.STEERING.SteeringAngle[internal]@Fahren; Dieser Faktor wird als Multiplikator für den Steuerung des Aktiven Rücklaufs benötigt. Vollständige Quantisierung/Offsetsangabe: (PH) = 0.00390625 * (HEX) + 0,0078125
          signal FACT_DMPNG_STMOM_FTAX: start 40, 8 bit, little-endian, base-type=uint8, invalid-value=value_255Dot0:255, compu {phys=raw/256+0.0078125 for raw -2..65022}, range phys 0..254, to EPS  # Faktor_Dämpfung_Lenkmoment_Vorderachse / factor_damping_steering-moment_front-axle | LogicalInterface:BMW.CHASSIS.STEERING.SteeringAngle[internal]@Fahren; Dieser Faktor wird als Multiplikator für den Steuerung des Aktiven Rücklaufs benötigt. Vollständige Quantisierung/Offsetsangabe: (PH) = 0.00390625 * (HEX) + 0.0078125
          signal QU_TAR_FACT_STMOM_FTAX: start 56, 4 bit, little-endian, base-type=uint8, invalid-value=value_15Dot0:15, compu {2=SollwerteUmsetzen (QU_TAR_FACT_STMOM_FTAX_SollwerteUmsetzen) (Es wird ein Lenkmoment angefordert. / BNE original name: Sollwerte umsetzen), 7=SollwerteNichtVorhanden (QU_TAR_FACT_STMOM_FTAX_SollwerteNichtVorhanden) (Wird immer gesetzt wenn keine EPS verbaut ist. / BNE original name: Sollwerte nicht vorhanden), 14=StandbyColonSollwerteNichtUmsetzen (QU_TAR_FACT_STMOM_FTAX_StandbyColonSollwerteNichtUmsetzen) (Es wird kein Moment angefordert. Wird auch im Fehlerfall gesetzt. / BNE original name: Standby: Sollwerte nicht umsetzen), 15=SignalUngueltig (QU_TAR_FACT_STMOM_FTAX_SignalUngueltig) (Wird nicht aktiv gesetzt / BNE original name: Signal ungültig)} "Qualifier_Soll_Faktor_Lenkmoment_Vorderachse / Qualifier_target_factor_steering-moment_front-axle", to EPS  # Qualifier_Soll_Faktor_Lenkmoment_Vorderachse / Qualifier_target_factor_steering-moment_front-axle | LogicalInterface:BMW.CHASSIS.STEERING.SteeringAngle[internal]@Fahren; Sollwertqualifier zu den Signalen Faktor_Unterstützung_Lenkmoment_Vorderachse, Faktor_Dämpfung_Lenkmoment_Vorderachse, Faktor_Zentrierung_Lenkmoment_Vorderachse
          signal QU_TAR_QTA_STMOM_DV: start 28, 4 bit, little-endian, base-type=uint8, invalid-value=value_15Dot0:15, compu {2=SollwerteUmsetzen (QU_TAR_QTA_STMOM_DV_SollwerteUmsetzen) (Es wird ein Lenkmoment angefordert. / BNE original name: Sollwerte umsetzen), 7=SollwerteNichtVorhanden (QU_TAR_QTA_STMOM_DV_SollwerteNichtVorhanden) (Wird gesendet, wenn die Funktion auscodiert ist. Wird immer gesetzt wenn keine EPS verbaut ist. / BNE original name: Sollwerte nicht vorhanden), 14=SollwerteNichtUmsetzen_Standby (QU_TAR_QTA_STMOM_DV_SollwerteNichtUmsetzen_Standby) (Es wird kein Moment angefordert. / BNE original name: Sollwerte nicht umsetzen - Standby), 15=SignalUngueltig (QU_TAR_QTA_STMOM_DV_SignalUngueltig) (Wird nicht aktiv gesetzt / BNE original name: Signal ungültig)} "Qualifier_Soll_Anteil_Lenkmoment_Fahrer / Qualifier_target_quota_steering-moment_driver", to EPS  # Qualifier_Soll_Anteil_Lenkmoment_Fahrer / Qualifier_target_quota_steering-moment_driver | LogicalInterface:BMW.CHASSIS.STEERING.SteeringAngle[internal]@Fahren; Sollwert-Qualifier zum Signal Soll_Anteil_Lenkmoment_Fahrer
          signal TAR_QTA_STMOM_DV: start 16, 12 bit, little-endian, base-type=uint16, invalid-value=value_4095Dot0:4095, compu {phys=raw*0.005-10 for raw 2000..802000; unit NwtMtr}, range phys 0..4000 NwtMtr, to EPS  # Soll_Anteil_Lenkmoment_Fahrer / target_quota_steering-moment_driver | LogicalInterface:BMW.CHASSIS.STABILIZATION.VehicleDynamicParameters[internal]@Fahren; Es handelt sich um das Offset-Handmoment des Lenkrades, das im Gegenuhrzeigersinn positiv gezählt wird.
          signal TAR_QTA_STRMOM_DV_dummy_12_15: start 12, 4 bit, little-endian, init-value=15, base-type=uint8, compu {identical}, range phys 0..15, to EPS
          mapping sigGroup_TAR_QTA_STRMOM_DV: i-signal-group=sigGroup_TAR_QTA_STRMOM_DV
        carries pdu TAR_STMOM_DV_ACT: packing-byte-order=little-endian, start-position=64
        pdu TAR_STMOM_DV_ACT: length=8, transmission-mode-true-timing=cyclic-timing=time-period=0.01, unused-bit-pattern=255  # Soll Lenkmoment Fahrer Stellglied | Diese Nachricht wird nur bei Fahrzeugen mit elektrischer Lenkung unterstützt. Das angegebene Offsetmoment wird vom ICM_QL Momentkoordinator gesendet und hinter der Reglerschleife aufaddiert, um eine direkte Korrekturmöglichkeit der Stellwerte zu haben.
          signal ALIV_TAR_STMOM_DV_ACT: start 8, 4 bit, little-endian, base-type=uint8, invalid-value=value_15Dot0:15, compu-method=ALIV_COU_4, to EPS  # Alive_Soll_Lenkmoment_Fahrer_Stellglied / alive_target_steering-moment_driver_actuator | LogicalInterface:BMW.CHASSIS.STABILIZATION.VehicleDynamicParameters[internal]@Fahren; Standardabsicherung Alivezähler laut Definition per Lastenheft Allgemeine Bordnetzkommunikation.
          signal CRC_TAR_STMOM_DV_ACT: start 0, 8 bit, little-endian, base-type=uint8, compu-method=CRC8, data-constr=CRC8, to EPS  # CRC_Soll_Lenkmoment_Fahrer_Stellglied / CRC_target_steering-moment_driver_actuator | LogicalInterface:BMW.CHASSIS.STABILIZATION.VehicleDynamicParameters[internal]@Fahren; Standardabsicherung Applikations-CRC laut Definition per Lastenheft Allgemeine Bordnetzkommunikation. Dieses Signal verwendet die Applikations-CRC-ID = 179 (Dez)
          signal FACT_DMPNG_ADDON_STMOM_FTAX: start 56, 8 bit, little-endian, base-type=uint8, invalid-value=value_255Dot0:255, compu {phys=raw/64 for raw 0..8192, 253=Reserviert (FACT_DMPNG_ADDON_STMOM_FTAX_Reserviert) (Hinweis: Reserviert für funktionale Kennung Signal-Tag.), 254=Reserviert_bne_5B8A124DE2884D68A663388C50F241EF_254 (FACT_DMPNG_ADDON_STMOM_FTAX_Reserviert_bne_5B8A124DE2884D68A663388C50F241EF_254) (Hinweis: Reserviert für funktionale Kennung Signal-Tag. / BNE original name: Reserviert), 255=Signal_unbefuellt (FACT_DMPNG_ADDON_STMOM_FTAX_Signal_unbefuellt) (Sendefunktion nicht in Betrieb)} "Faktor_Dämpfung_Zusatz_Lenkmoment_Vorderachse / factor_damping_add-on_steering-moment_front-axle", range phys 0..128 "Faktor_Dämpfung_Zusatz_Lenkmoment_Vorderachse / factor_damping_add-on_steering-moment_front-axle", to EPS  # Faktor_Dämpfung_Zusatz_Lenkmoment_Vorderachse / factor_damping_add-on_steering-moment_front-axle | LogicalInterface:BMW.CHASSIS.STABILIZATION.VehicleDynamicParameters[internal]@Fahren; Skalierung der Zusatzdämpfung in der EPS für steife Lenkwinkelregelung in der SWC QdmZff.
          signal QU_TAR_DMPNG_ADDON_STMOM_FTAX: start 52, 4 bit, little-endian, base-type=uint8, invalid-value=value_15Dot0:15, compu {1=SollwertZusatzdaempfungNichtUmsetzen (QU_TAR_DMPNG_ADDON_STMOM_FTAX_SollwertZusatzdaempfungNichtUmsetzen) (BNE original name: Sollwert Zusatzdämpfung nicht umsetzen), 2=SollwertZusatzdaempfungUmsetzen (QU_TAR_DMPNG_ADDON_STMOM_FTAX_SollwertZusatzdaempfungUmsetzen) (BNE original name: Sollwert Zusatzdämpfung umsetzen), 15=SignalUnbefuellt (QU_TAR_DMPNG_ADDON_STMOM_FTAX_SignalUnbefuellt) (Wird nicht aktiv gesetzt / BNE original name: Signal unbefüllt)} "Qualifier_Soll_Dämpfung_Zusatz_Lenkmoment_Vorderachse / Qualifier_target_damping_add-on_steering-moment_front-axle", to EPS  # Qualifier_Soll_Dämpfung_Zusatz_Lenkmoment_Vorderachse / Qualifier_target_damping_add-on_steering-moment_front-axle | LogicalInterface:BMW.CHASSIS.STABILIZATION.VehicleDynamicParameters[internal]@Fahren; Sollwertqualifier zum Signal Faktor_Dämpfung_Zusatz_Lenkmoment_Vorderachse
          signal QU_TAR_STMOM_DV_ACT: start 28, 4 bit, little-endian, base-type=uint8, invalid-value=value_15Dot0:15, compu {2=SollwerteUmsetzen (QU_TAR_STMOM_DV_ACT_SollwerteUmsetzen) (Es wird ein Lenkmoment angefordert. / BNE original name: Sollwerte umsetzen), 7=SollwerteNichtVorhanden (QU_TAR_STMOM_DV_ACT_SollwerteNichtVorhanden) (Wird immer gesetzt wenn keine EPS verbaut ist / BNE original name: Sollwerte nicht vorhanden), 14=StandbyColonSollwerteNichtUmsetzen (QU_TAR_STMOM_DV_ACT_StandbyColonSollwerteNichtUmsetzen) (Es wird kein Moment angefordert. Wird auch im Fehlerfall gesetzt. / BNE original name: Standby: Sollwerte nicht umsetzen), 15=SignalUngueltig (QU_TAR_STMOM_DV_ACT_SignalUngueltig) (Wird nicht aktiv gesetzt / BNE original name: Signal ungültig)} "Qualifier_Soll_Lenkmoment_Fahrer_Stellglied / Qualifier_target_steering-moment_driver_actuator", to EPS  # Qualifier_Soll_Lenkmoment_Fahrer_Stellglied / Qualifier_target_steering-moment_driver_actuator | LogicalInterface:BMW.CHASSIS.STABILIZATION.VehicleDynamicParameters[internal]@Fahren; Sollwertqualifier zum Signal Soll_Lenkmoment_Fahrer_Stellglied
          signal TAR_STMOM_DV_ACT: start 16, 12 bit, little-endian, base-type=uint16, invalid-value=value_4095Dot0:4095, compu {phys=raw*0.006-12 for raw 2000..668666.6666666666; unit NwtMtr}, range phys 0..4000 NwtMtr, to EPS  # Soll_Lenkmoment_Fahrer_Stellglied / target_steering-moment_driver_actuator | LogicalInterface:BMW.CHASSIS.STABILIZATION.VehicleDynamicParameters[internal]@Fahren; Gestelltes Motormoment für den EPS Aktuator. Offsetmoment (+/-1Nm).
          signal TAR_STMOM_DV_ACT_dummy_12_15: start 12, 4 bit, little-endian, init-value=15, base-type=uint8, compu {identical}, range phys 0..15, to EPS
          signal TAR_STMOM_DV_ACT_dummy_32_51: start 32, 20 bit, little-endian, init-value=1048575, base-type=uint32, compu {identical}, range phys 0..1048575, to EPS
          mapping sigGroup_TAR_STMOM_DV_ACT: i-signal-group=sigGroup_TAR_STMOM_DV_ACT
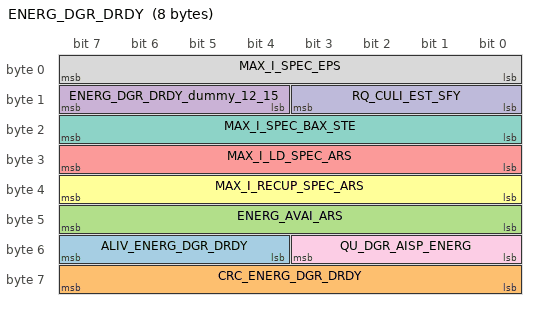
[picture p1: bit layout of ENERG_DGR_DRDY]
      frame ENERG_DGR_DRDY: to EPS, category=APPLICATION, frame-length=8, flexray-absolutely-scheduled-timing{communication-cycle=cycle-repetition={base-cycle=1, cycle-repetition=CYCLE-REPETITION-2}, slot-id=68}, allow-dynamic-l-sdu-length=false, payload-preamble-indicator=false  # Energie Degradation Fahrdynamik
        pdu ENERG_DGR_DRDY: length=8, transmission-mode-true-timing=cyclic-timing=time-period={tolerance=absolute-tolerance=0.002, value=0.01}, unused-bit-pattern=255  # Energie Degradation Fahrdynamik | Energie Degradation fahrdynamischer Regelsysteme: Diese PDU enthält die Max-Strom-Vorgaben für EPS, ASA, HSR, emARS und einen Funktionsqualifier zur Degradation von EHC1/2
          signal ALIV_ENERG_DGR_DRDY: start 52, 4 bit, little-endian, base-type=uint8, invalid-value=value_15Dot0:15, compu {identical}, range phys 0..14, to EPS  # Alive_Energie_Degradation_Fahrdynamik / alive_Energy_degradation_driving-dynamics | LogicalInterface:BMW.POWERTRAIN.GENERATOR.EnergySupplySafe[internal]@Fahren; Standardabsicherung Alivezähler laut Definition per Lastenheft Allgemeine Bordnetzkommunikation.
          signal CRC_ENERG_DGR_DRDY: start 56, 8 bit, little-endian, base-type=uint8, compu-method=CRC8, data-constr=CRC8, to EPS  # CRC_Energie_Degradation_Fahrdynamik / CRC_Energy_degradation_driving-dynamics | LogicalInterface:BMW.POWERTRAIN.GENERATOR.EnergySupplySafe[internal]@Fahren; Standardabsicherung Applikations-CRC laut Definition per Lastenheft Allgemeine Bordnetzkommunikation. Dieses Signal verwendet die Applikations-CRC-ID = 56 (dez) = 38 (hex). Dieses Signal beinhaltet die CRC-Checksumme für die erweiterte Standardabsicherung mit Applikations-CRC nach Anwendungsprofil 1A E2E-Protection (Autosar SWS 428), mit abweichender Platzierung des CRC in Byte 7 (M10-Verfahren).
          signal ENERG_AVAI_ARS: start 40, 8 bit, little-endian, base-type=uint8, invalid-value=value_255Dot0:255, compu {0..100, 253=Funktionsschnittstelle_ist_nicht_verfuegbar (ENERG_AVAI_ARS_Funktionsschnittstelle_ist_nicht_verfuegbar) (Sendefunktion in Betrieb, Werte nicht verfügbar), 254=Funktion_meldet_Fehler (ENERG_AVAI_ARS_Funktion_meldet_Fehler) (Nutzsignal kann nicht berechnet werden), 255=Signal_unbefuellt (ENERG_AVAI_ARS_Signal_unbefuellt) (Sendefunktion nicht in Betrieb); unit Perc} "Energie_Verfügbarkeit_ARS / Energy_availibility_ARS", range phys 0..100 Perc "Energie_Verfügbarkeit_ARS / Energy_availibility_ARS", to EPS  # Energie_Verfügbarkeit_ARS / Energy_availibility_ARS | LogicalInterface:BMW.CHASSIS.LOWVOLTAGE.EnergyManagementELMaExt[internal]@Fahren; Es handelt sich um ein qualitatives Signal, das die verfügbare Energie der emARS-Bordnetzerweiterung und daraus resultierend die Degradationsstufe des emARS-Gesamtsystems beschreibt. Defaultwert ist 100%.
          signal ENERG_DGR_DRDY_dummy_12_15: start 12, 4 bit, little-endian, init-value=15, base-type=uint8, compu {identical}, range phys 0..15, to EPS
          signal MAX_I_LD_SPEC_ARS: start 24, 8 bit, little-endian, base-type=uint8, invalid-value=value_255Dot0:255, compu-method=I_SPEC_ARS, data-constr=I_SPEC_ARS, to EPS  # Maximal_Strom_Last_Vorgabe_ARS / maximum_current_load_specification_ARS | LogicalInterface:BMW.CHASSIS.LOWVOLTAGE.EnergyManagementELMaExt[internal]@Fahren; Es handel sich um den maximal zulässigen DC-Last-Strom beider emARS-Aktuatoren in Summe. Default-Wert ist 240 A.
          signal MAX_I_RECUP_SPEC_ARS: start 32, 8 bit, little-endian, base-type=uint8, invalid-value=value_255Dot0:255, compu {phys=raw-252 for raw 252..504, 253=Funktionsschnittstelle_ist_nicht_verfuegbar (MIN_I_SPEC_ARS_Funktionsschnittstelle_ist_nicht_verfuegbar) (Sendefunktion in Betrieb, Werte nicht verfügbar), 254=Funktion_meldet_Fehler (MIN_I_SPEC_ARS_Funktion_meldet_Fehler) (Nutzsignal kann nicht berechnet werden), 255=Signal_unbefuellt (MIN_I_SPEC_ARS_Signal_unbefuellt) (Sendefunktion nicht in Betrieb); unit ampere} "Minimal_Strom_Vorgabe_ARS / minimum_current_specification_ARS", range phys 0..252 ampere "Minimal_Strom_Vorgabe_ARS / minimum_current_specification_ARS", to EPS  # Maximal_Strom_Rekuperation_Vorgabe_ARS / maximum_current_recuperation_specification_ARS | LogicalInterface:BMW.CHASSIS.LOWVOLTAGE.EnergyManagementELMaExt[internal]@Fahren; Es handelt sich um den maximal zulässigen DC-REKU-Strom, welchen beide emARS-Aktuatoren ins Energiebordnetz zurückspeisen/ rekuperieren dürfen. Default-Wert ist -240 A.
          signal MAX_I_SPEC_BAX_STE: start 16, 8 bit, little-endian, base-type=uint8, invalid-value=value_255Dot0:255, compu-method=I_SPEC_ARS, data-constr=I_SPEC_ARS, to EPS  # Maximal_Strom_Vorgabe_Hinterachse_Lenkung / maximum_current_specification_back-axle_steering | LogicalInterface:BMW.CHASSIS.LOWVOLTAGE.EnergyManagementELMa[internal]@Fahren; Es handel sich um den maximal zulässigen DC-Last-Strom am Stecker des Lenkungsstellers der Hinterachse (HSR-Steller). Default-Wert ist 70 A.
          signal MAX_I_SPEC_EPS: start 0, 8 bit, little-endian, base-type=uint8, invalid-value=value_255Dot0:255, compu-method=I_SPEC_ARS, data-constr=I_SPEC_ARS, to EPS  # Maximal_Strom_Vorgabe_EPS / maximum_current_specification_EPS | LogicalInterface:BMW.CHASSIS.LOWVOLTAGE.EnergyManagementELMa[internal]@Fahren; Es handel sich um den maximal zulässigen DC-Last-Strom am Stecker der elektrischen Lenkmomentenunterstützung (EPS-Motor). Default-Wert ist 120 A.
          signal QU_DGR_AISP_ENERG: start 48, 4 bit, little-endian, base-type=uint8, invalid-value=value_15Dot0:15, compu {0=Degradationsstufe0 (QU_DGR_AISP_ENERG_Degradationsstufe0) (Keine Anlaufverzögerung oder Anlaufunterbrechung des Kompressors Incl. Default- und Aufstartwert / BNE original name: Degradationsstufe 0), 1=Degradationsstufe1 (QU_DGR_AISP_ENERG_Degradationsstufe1) (Geringe Anlaufverzögerung (Geringe Aufweitung der Anregelschwellen, keine Anlaufsperre oder -unterbrechung) / BNE original name: Degradationsstufe 1), 2=Degradationsstufe2 (QU_DGR_AISP_ENERG_Degradationsstufe2) (Mittlere Anlaufverzögerung (Mittlere Aufweitung der Anregelschwellen, keine Anlaufsperre oder -unterbrechung) / BNE original name: Degradationsstufe 2), 3=Degradationsstufe3 (QU_DGR_AISP_ENERG_Degradationsstufe3) (Maximale Anlaufverzögerung (Maximale Aufweitung der Anregelschwellen, keine Anlaufsperre oder -unterbrechung) / BNE original name: Degradationsstufe 3), 4=Degradationsstufe4 (QU_DGR_AISP_ENERG_Degradationsstufe4) (Anlaufsperre für definierte Zeitspanne oder Anlaufunterbrechung / BNE original name: Degradationsstufe 4), 15=SignalUngueltig (QU_DGR_AISP_ENERG_SignalUngueltig) (BNE original name: Signal ungültig)} "Qualifier_Degradation_Luftfeder_Energie / Qualifier_degradation_air-spring_Energy", to EPS  # Qualifier_Degradation_Luftfeder_Energie / Qualifier_degradation_air-spring_Energy | LogicalInterface:BMW.CHASSIS.LOWVOLTAGE.EnergyManagementELMa[internal]@Fahren; Es handelt sich um einen Funktionsqualifier, um den Anlauf des Kompressors der Luftfederung bedarfsgerecht zu verzögern oder zu unterbrechen.
          signal RQ_CULI_EST_SFY: start 8, 4 bit, little-endian, base-type=uint8, invalid-value=value_15Dot0:15, compu {0=Keine_Strombegrenzung (RQ_CULI_EST_SFY_Keine_Strombegrenzung) (Keine Strombegrenzung angefordert.), 1=Komfort_Strombegrenzung (RQ_CULI_EST_SFY_Komfort_Strombegrenzung) (Strombegrenzung über ELMa angefordert.), 10=Maximale_Strombegrenzung (RQ_CULI_EST_SFY_Maximale_Strombegrenzung) (Sicherheits-Strombegrenzung angefordert.), 13=Reserviert_nicht_verfuegbar (RQ_CULI_EST_SFY_Reserviert_nicht_verfuegbar) (Hinweis: Reserviert für funktionale Kennung Signal-Tag.), 14=Reserviert_Fehler (RQ_CULI_EST_SFY_Reserviert_Fehler) (Hinweis: Reserviert für funktionale Kennung Signal-Tag.), 15=Signal_unbefuellt (RQ_CULI_EST_SFY_Signal_unbefuellt) (Sendefunktion nicht in Betrieb)} "Anforderung_Strombegrenzung_Elektrische-Lenkung_Sicherheit / request_current-limitation_electrical-steering_safety", to EPS  # Anforderung_Strombegrenzung_Elektrische-Lenkung_Sicherheit / request_current-limitation_electrical-steering_safety | LogicalInterface:BMW.POWERTRAIN.GENERATOR.EnergySupplySafe[internal]@Fahren; In diesem Signal wird der Elektrischen Lenkung übermittelt, ob und in welchem Umfang Anforderungen an eine Strombegrenzung der elektrischen Lenkung bestehen.
          mapping sigGroup_ENERG_DGR_DRDY: i-signal-group=sigGroup_ENERG_DGR_DRDY
      frame xcpstatic: from EPS, category=XCP_RUNTIME_CONFIGURED, frame-length=16, flexray-absolutely-scheduled-timing{communication-cycle=cycle-repetition={base-cycle=0, cycle-repetition=CYCLE-REPETITION-1}, slot-id=8}, allow-dynamic-l-sdu-length=false, payload-preamble-indicator=false  # XCP Bereich Statisch / XCP Frame Static | Dieser Frame dient als Platzhalter für die XCP-Konfiguration für FlexRay (s. LH FlexRay) und zur Pufferkonfiguration der FlexRay-Controller. Der statische XCP-Bereich wird auch durch das Projekt "Funktionstrace" mitbenutzt. Ansprechpartner ist Florian Kuttig oder Christian Pigorsch. / Dummyframe für Infrastruktur XCP
        carries pdu dummy16bstatic: packing-byte-order=little-endian, start-position=0
        general purpose i pdu dummy16bstatic: category=XCP, length=16  # Dummy-PDU 16 Byte static | Dummy-PDU ohne inhaltliche Verbindlichkeit mit 16 Byte für Infrastruktur (z.B. XCP).
      frame xcpstatic: from EPS, category=XCP_RUNTIME_CONFIGURED, frame-length=16, flexray-absolutely-scheduled-timing{communication-cycle=cycle-repetition={base-cycle=0, cycle-repetition=CYCLE-REPETITION-1}, slot-id=9}, allow-dynamic-l-sdu-length=false, payload-preamble-indicator=false  # XCP Bereich Statisch / XCP Frame Static | Dieser Frame dient als Platzhalter für die XCP-Konfiguration für FlexRay (s. LH FlexRay) und zur Pufferkonfiguration der FlexRay-Controller. Der statische XCP-Bereich wird auch durch das Projekt "Funktionstrace" mitbenutzt. Ansprechpartner ist Florian Kuttig oder Christian Pigorsch. / Dummyframe für Infrastruktur XCP
        carries pdu dummy16bstatic: packing-byte-order=little-endian, start-position=0
      pdu triggering pduTrig_ANFRAGE: pdu=ANFRAGE, from EPS, to EPS
      pdu triggering pduTrig_DBG_EPS_BS_MOD_58_BYTE: pdu=DBG_EPS_BS_MOD_58_BYTE, from EPS
      pdu triggering pduTrig_DBG_EPS_MOD_EXT_120_BYTE: pdu=DBG_EPS_MOD_EXT_120_BYTE, from EPS
      pdu triggering pduTrig_RQ_STG_EFAN: pdu=RQ_STG_EFAN, from EPS
      pdu triggering pduTrig_SECU_CHAL: pdu=SECU_CHAL, from EPS
      pdu triggering pduTrig_SECU_RESP: pdu=SECU_RESP, to EPS
package /BMW/Boardnet/CodingDatatypes/CompuMethodsForBoardnet
  compu method ALIV_COU_4: 0=Zaehlerstand0DotDotE (ALIV_COU_4_Zaehlerstand0DotDotE) (Nach dem Zählerstand 14 wird zyklisch bei 0 wieder begonnen. / After counter reading 14, the counter restarts at 0 again in cycles / BNE original name: Zählerstand 0..E), 15=SignalUngueltig (ALIV_COU_4_SignalUngueltig) (BNE original name: Signal ungültig)  # Alive_Zähler_4 / alive_counter_4
  compu method CRC8: identical  # Standartabsicherung Apllikations-CRC.
  compu method DIAG_ST_OBD: identical  # Diagnose_Status_OBD / diagnosis_status_OBD
  compu method I_SPEC_ARS: 0..252, 253=Funktionsschnittstelle_ist_nicht_verfuegbar (I_SPEC_ARS_Funktionsschnittstelle_ist_nicht_verfuegbar) (Sendefunktion in Betrieb, Werte nicht verfügbar), 254=Funktion_meldet_Fehler (I_SPEC_ARS_Funktion_meldet_Fehler) (Nutzsignal kann nicht berechnet werden), 255=Signal_unbefuellt (I_SPEC_ARS_Signal_unbefuellt) (Sendefunktion nicht in Betrieb); unit ampere  # Strom_Vorgabe_ARS / current_specification_ARS
  compu method QU_AVL_RPM_WHL: 8=Initialisierung (QU_AVL_RPM_WHL_Initialisierung) (Wird gelegt solange aufgrund des Aufstartvorgangs (und der dazu gehörenden Sensorprüfung) für den zugehörigen Raddrehzahlsensor kein Wert ermittelt werden kann. Nutzsignal wird permanent mit der Ungültigkeitskennung befüllt.), 1=SignalwertIstGueltigUndAbgesichertUndPlausibilisiert (QU_AVL_RPM_WHL_SignalwertIstGueltigUndAbgesichertUndPlausibilisiert) (Ist der zugehörige Raddrehzahlsensor i.O. geprüft, so wird der Qualifier auf diesem Zustand gesetzt. / BNE original name: Signalwert ist gültig und abgesichert und plausibilisiert), 9=Reserved (QU_AVL_RPM_WHL_Reserved), 2=Reserved_bne_BFE56DC998394BD9A8FED9E096CC9242_2 (QU_AVL_RPM_WHL_Reserved_bne_BFE56DC998394BD9A8FED9E096CC9242_2) (BNE original name: Reserved), 10=Reserved_bne_BFE56DC998394BD9A8FED9E096CC9242_10 (QU_AVL_RPM_WHL_Reserved_bne_BFE56DC998394BD9A8FED9E096CC9242_10) (BNE original name: Reserved), 3=Reserved_bne_BFE56DC998394BD9A8FED9E096CC9242_3 (QU_AVL_RPM_WHL_Reserved_bne_BFE56DC998394BD9A8FED9E096CC9242_3) (BNE original name: Reserved), 11=SignalqualitaetBzwDotUeberwachungEingeschraenktZustandSlashStatusTemporaer (QU_AVL_RPM_WHL_SignalqualitaetBzwDotUeberwachungEingeschraenktZustandSlashStatusTemporaer) (Implementierungsinfo des DSC-8 Bosch-Systems: Wird gelegt, wenn bei gesetzter Rollenerkennung des ICM-Q/L die Anfahrüberwachung des DSC zuschlägt. / BNE original name: Signalqualität bzw. Überwachung eingeschränkt, Zustand/Status temporär), 4=ErsatzwertIstImNutzsignalGesetzt (QU_AVL_RPM_WHL_ErsatzwertIstImNutzsignalGesetzt) (Wird gelegt, solange keine gültige Drehrichtung erkannt wurde. (z.B. Stillstand) Kann nur bei Sensoren mit Drehrichtungserkennung gesetzt werden. / BNE original name: Ersatzwert ist im Nutzsignal gesetzt), 12=ErsatzwertIstImNutzsignalGesetztZustandSlashStatusTemporaer (QU_AVL_RPM_WHL_ErsatzwertIstImNutzsignalGesetztZustandSlashStatusTemporaer) (Nutzsignal liefert das aktuelle Rohsignal mit eingeschränkter Qualität (es kann zu Abweichungen kommen). Der Übergang zum "Signalwert ist gültig" (0001) erfolgt über eine Einschwingphase (ca. 300ms) Kann auftreten während bzw. nach Unterspannung am Raddrehzahlsensor (DSC) In der PL6 wird dieser Code nicht verwendet. / BNE original name: Ersatzwert ist im Nutzsignal gesetzt Zustand / Status Temporär), 6=Wert_nicht_verfuegbar_Fehler_elektrisch (QU_AVL_RPM_WHL_Wert_nicht_verfuegbar_Fehler_elektrisch) (Im Fehlerfall wird abhängig von der Ursache entweder 0110 (Schwerpunkt: elektrische Fehler mit Reparaturbedarf) oder 1110 (Schwerpunkt: Plausibilitätsfehler ohne Reparaturbedarf) gesendet. Die Umsetzung ist produktlinienspezifisch unterschiedlich. Nutzsignal wird permanent mit der Ungültigkeitskennung befüllt.), 14=Wert_nicht_verfuegbar_Plausibilitaetsfehler (QU_AVL_RPM_WHL_Wert_nicht_verfuegbar_Plausibilitaetsfehler) (Im Fehlerfall wird abhängig von der Ursache entweder 0110 (Schwerpunkt: elektrische Fehler mit Reparaturbedarf) oder 1110 (Schwerpunkt: Plausibilitätsfehler ohne Reparaturbedarf) gesendet. Die Umsetzung ist produktlinienspezifisch unterschiedlich. Nutzsignal wird permanent mit der Ungültigkeitskennung befüllt.), 7=Reserved_bne_BFE56DC998394BD9A8FED9E096CC9242_7 (QU_AVL_RPM_WHL_Reserved_bne_BFE56DC998394BD9A8FED9E096CC9242_7) (BNE original name: Reserved), 15=SignalUngueltig (QU_AVL_RPM_WHL_SignalUngueltig) (Kann nur vom Gateway gesetzt werden / BNE original name: Signal ungültig)  # Qualifier_Ist_Drehzahl_Rad / Qualifier_actual-value_RPM_wheel
  compu method SSV_IDENT: 0=REF_BAC4CAN_VIN (SSV_IDENT_REF_BAC4CAN_VIN), 1=DME1VIN (SSV_IDENT_DME1VIN) (BNE original name: DME1 VIN), 2=DME2VIN (SSV_IDENT_DME2VIN) (BNE original name: DME2 VIN), 3=RSEVIN (SSV_IDENT_RSEVIN) (Vorhalt / BNE original name: RSE VIN), 4=KAFASVIN (SSV_IDENT_KAFASVIN) (Vorhalt / BNE original name: KAFAS, VIN), 5=DSC_ModulVIN (SSV_IDENT_DSC_ModulVIN) (Vorhalt / BNE original name: DSC_Modul VIN), 6=VDPVIN (SSV_IDENT_VDPVIN) (Vorhalt / BNE original name: VDP VIN), 7=SASVIN (SSV_IDENT_SASVIN) (Vorhalt / BNE original name: SAS VIN), 8=NiViVIN (SSV_IDENT_NiViVIN) (Vorhalt / BNE original name: NiVi VIN), 9=HU_VIN (SSV_IDENT_HU_VIN) (Alle HUs), 10=EPS_VIN (SSV_IDENT_EPS_VIN) (Vorhalt), 11=REF_BAC4_FR_VIN (SSV_IDENT_REF_BAC4_FR_VIN), 19=MRR_VIN (SSV_IDENT_MRR_VIN), 20=ATM2_VIN (SSV_IDENT_ATM2_VIN), 21=Kombi_VIN (SSV_IDENT_Kombi_VIN), 255=SignalUngueltig (SSV_IDENT_SignalUngueltig) (BNE original name: Signal ungültig)  # SSV_Identifikation / SSV_identification
package /BMW/Boardnet/CodingDatatypes/DataConstraints
  range CRC8: phys 0..255  # Standartabsicherung Apllikations-CRC.
  range DIAG_ST_OBD: phys 0..63  # Diagnose_Status_OBD / diagnosis_status_OBD
  range I_SPEC_ARS: phys 0..252 ampere  # Strom_Vorgabe_ARS / current_specification_ARS
package /BMW/Boardnet/CodingDatatypes/SwBaseTypes
  base type ascii8: category=FIXED_LENGTH, base-type-size=8, base-type-encoding=ISO-8859-1, mem-alignment=8, native-declaration=unsigned char
package /BMW/Boardnet/Ecus/EcuInstances
  ecu instance EPS: client-id-range={lower-limit=12288, upper-limit=12543}, diagnostic-address=48, sleep-mode-supported=false, wake-up-over-bus-supported=false  # Electrical Power - Assist - Steering | Achsparalleles EPS (electrical power-assist steering): System steuert unmittelbar Lenkschenkel an | MCV 0.98.217
    flexray communication controller EPS_A_FlexRay:  # component: Electrical Power - Assist - Steering, bus: A-FlexRay / component: , bus: A-FlexRay
      accepted-startup-range=212
      allow-halt-due-to-clock=true
      allow-passive-to-active=0
      cluster-drift-damping=2
      decoding-correction=48
      delay-compensation-a=1
      delay-compensation-b=1
      extern-offset-correction=0
      extern-rate-correction=0
      key-slot-id=0
      key-slot-only-enabled=false
      key-slot-used-for-start-up=false
      key-slot-used-for-sync=false
      latest-tx=269
      listen-timeout=400242
      macro-initial-offset-a=3
      macro-initial-offset-b=3
      maximum-dynamic-payload-length=60
      micro-initial-offset-a=6
      micro-initial-offset-b=6
      micro-per-cycle=200000
      microtick-duration=2.5E-8
      offset-correction-out=126
      rate-correction-out=121
      samples-per-microtick=2
      wake-up-pattern=33
    flexray communication connector con_EPS_FibexID_0b7e5e09c061465d913e8968ece3cded: comm-controller=EPS_A_FlexRay, wake-up-channel=true
package /BMW/Boardnet/Pdus/ISignalGroups
  18 x i signal group:
    sigGroup_ACLNY_MASSCNTR: i-signal=[ACLNY_COG, ACLNY_COG_ERR_AMP, ACLNY_MASSCNTR_dummy_12_15, ALIV_ACLNY_COG, CRC_ACLNY_COG, QU_ACLNY_COG], system-signal-group=sigGroup_ACLNY_MASSCNTR
    sigGroup_AVL_FORC_GRD: i-signal=[ALIV_AVL_FORC_GRD, AVL_FORC_GRD, AVL_FORC_GRD_dummy_12_15, AVL_PWR_EL_EPS_COOD, CRC_AVL_FORC_GRD, QU_AVL_FORC_GRD], system-signal-group=sigGroup_AVL_FORC_GRD
    sigGroup_AVL_PO_EPS: i-signal=[ALIV_AVL_PO_EPS, AVL_PO_EPS, AVL_PO_IDX_EPS, CRC_AVL_PO_EPS, IDX_TORQ_SEN, OFFS_GRD_MID_EPS, QU_AVL_PO_EPS, UN_PO_EPS], system-signal-group=sigGroup_AVL_PO_EPS
    sigGroup_AVL_RPM_WHL: i-signal=[ALIV_AVL_RPM_WHL, AVL_RPM_WHL_FLH, AVL_RPM_WHL_FRH, AVL_RPM_WHL_RLH, AVL_RPM_WHL_RRH, AVL_RPM_WHL_dummy_12_15, CRC_AVL_RPM_WHL, QU_AVL_RPM_WHL_FLH, QU_AVL_RPM_WHL_FRH, QU_AVL_RPM_WHL_RLH, QU_AVL_RPM_WHL_RRH], system-signal-group=sigGroup_AVL_RPM_WHL
    sigGroup_AVL_STMOM_DV_ACT: i-signal=[ALIV_AVL_STMOM_DV_ACT, AVL_STMOM_DV_ACT, AVL_STMOM_DV_ACT_dummy_12_15, CRC_AVL_STMOM_DV_ACT, QU_AVL_STMOM_DV_ACT], system-signal-group=sigGroup_AVL_STMOM_DV_ACT
    sigGroup_CON_VEH: i-signal=[ALIV_CON_VEH, CON_VEH_dummy_56_63, CRC_CON_VEH, CTR_BS_PRTNT, CTR_FKTN_PRTNT, QU_ST_CON_VEH, ST_CON_VEH], system-signal-group=sigGroup_CON_VEH
    sigGroup_DISP_CC_EPS: i-signal=[ALIV_DISP_CC_EPS, CHL_DISP_CC_EPS, CRC_DISP_CC_EPS, NO_CC_EPS, ST_CC_EPS, ST_IDC_CC_EPS, TRANF_CC_EPS], system-signal-group=sigGroup_DISP_CC_EPS
    sigGroup_DT_EST: i-signal=[ALIV_DT_EST, AVL_I_ACT_EST, CRC_DT_EST, DT_EST_dummy_12_15, DT_EST_dummy_16_47, DT_EST_dummy_64_95, DT_EST_dummy_96_127, QU_AVL_I_ACT_EST, ST_CULI_EST], system-signal-group=sigGroup_DT_EST
    sigGroup_ENERG_DGR_DRDY: i-signal=[ALIV_ENERG_DGR_DRDY, CRC_ENERG_DGR_DRDY, ENERG_AVAI_ARS, ENERG_DGR_DRDY_dummy_12_15, MAX_I_LD_SPEC_ARS, MAX_I_RECUP_SPEC_ARS, MAX_I_SPEC_BAX_STE, MAX_I_SPEC_EPS, QU_DGR_AISP_ENERG, RQ_CULI_EST_SFY], system-signal-group=sigGroup_ENERG_DGR_DRDY
    sigGroup_ENSU_SFY: i-signal=[ALIV_ENSU_SFY, CHL_ENSU_SFY, CRC_ENSU_SFY, ENSU_SFY_dummy_28_31, ENSU_SFY_dummy_32_63, QU_FN_ENSU_SFY, RQ_CULI], system-signal-group=sigGroup_ENSU_SFY
    sigGroup_OFFS_QUAD_EPS: i-signal=[ALIV_OFFS_QUAD_EPS, AVL_PO_IDX_ICM, CRC_OFFS_QUAD_EPS, OFFS_QUAD_RTR_EPS, ST_OFFS_QUAD_EPS], system-signal-group=sigGroup_OFFS_QUAD_EPS
    sigGroup_ST_EST: i-signal=[ALIV_ST_EST_FTAX, CRC_ST_EST_FTAX, QU_FN_EST, QU_FN_VIB_EPS, QU_SER_STMOM_DV_ACT, ST_EST_dummy_16_23], system-signal-group=sigGroup_ST_EST
    sigGroup_SU_EPS: i-signal=[ALIV_SU_EPS, CRC_SU_EPS, SU_EPS_dummy_14_19, SU_EPS_dummy_20_51, TOT_STR_EPS, UN_TOT_STR_EPS], system-signal-group=sigGroup_SU_EPS
    sigGroup_TAR_ESTP_VIRT_FTAX: i-signal=[ACTVN_FN_ESTP_VIRT_FTAX, ALIV_TAR_ESTP_VIRT_FTAX, CRC_TAR_ESTP_VIRT_FTAX, TAR_ESTP_VIRT_FTAX_dummy_12_31, TAR_ESTP_VIRT_FTAX_dummy_36_63], system-signal-group=sigGroup_TAR_ESTP_VIRT_FTAX
    sigGroup_TAR_QTA_STRMOM_DV: i-signal=[ALIV_TAR_QTA_STMOM_DV, CRC_TAR_QTA_STMOM_DV, CTR_DEAC_EPS_FNS, FACT_ASS_STMOM_FTAX, FACT_CTRR_STMOM_FTAX, FACT_DMPNG_STMOM_FTAX, QU_TAR_FACT_STMOM_FTAX, QU_TAR_QTA_STMOM_DV, TAR_QTA_STMOM_DV, TAR_QTA_STRMOM_DV_dummy_12_15], system-signal-group=sigGroup_TAR_QTA_STRMOM_DV
    sigGroup_TAR_STMOM_DV_ACT: i-signal=[ALIV_TAR_STMOM_DV_ACT, CRC_TAR_STMOM_DV_ACT, FACT_DMPNG_ADDON_STMOM_FTAX, QU_TAR_DMPNG_ADDON_STMOM_FTAX, QU_TAR_STMOM_DV_ACT, TAR_STMOM_DV_ACT, TAR_STMOM_DV_ACT_dummy_12_15, TAR_STMOM_DV_ACT_dummy_32_51], system-signal-group=sigGroup_TAR_STMOM_DV_ACT
    sigGroup_VYAW_VEH: i-signal=[ALIV_VYAW_VEH, CRC_VYAW_VEH, QU_VYAW_VEH, VYAW_VEH, VYAW_VEH_ERR_AMP, VYAW_VEH_dummy_12_15], system-signal-group=sigGroup_VYAW_VEH
    sigGroup_V_VEH: i-signal=[ALIV_V_VEH, CRC_V_VEH, DVCO_VEH, QU_V_VEH_COG, ST_V_VEH_NSS, V_VEH_COG, V_VEH_dummy_39_39], system-signal-group=sigGroup_V_VEH
package /BMW/Boardnet/Pdus/PDUs
  pdu ANFRAGE: length=8, minimum-delay=0.5, transmission-mode-true-timing=event-controlled-timing=number-of-repetitions=0, unused-bit-pattern=255  # Anfrage / Inquiry | Diese PDU löst die bis einschließlich SP2015 gültige Version der gleichnamigen PDU ab. Ab SP2018 darf nur noch diese Version der PDU verwendet werden. Mit dem Anfrage-Dienst kann eine Nachricht, die als anfragbar definiert ist, angefragt werden.
    signal ANFRAGE_ID2: start 0, 8 bit, little-endian, init-value=SWITCH_CODE:1, base-type=uint8, transfer-property=PENDING, to EPS
    signal ID_FN_INQY: start 8, 16 bit, little-endian, base-type=uint16, invalid-value=value_65535Dot0:65535, compu {41216=BedienungTastenEntertainment (ID_FN_INQY_BedienungTastenEntertainment) (BNE original name: Bedienung Tasten Entertainment), 62976=SteuerungAussenspiegel (ID_FN_INQY_SteuerungAussenspiegel) (BNE original name: Steuerung Außenspiegel), 57857=SicherFahrgestellnummer (ID_FN_INQY_SicherFahrgestellnummer) (BNE original name: Sicher Fahrgestellnummer), 9730=Regensensor_Wischergeschwindigkeit (ID_FN_INQY_Regensensor_Wischergeschwindigkeit) (BNE original name: Regensensor-Wischergeschwindigkeit), 14850=StatusFunkschluessel (ID_FN_INQY_StatusFunkschluessel) (BNE original name: Status Funkschlüssel), 26370=BedienungTastgeberBedienelementFront (ID_FN_INQY_BedienungTastgeberBedienelementFront) (BNE original name: Bedienung Tastgeber Bedienelement Front), 32258=StatusVerdeckCabrio (ID_FN_INQY_StatusVerdeckCabrio) (Wird ab BN2020 nur noch von HMI verwendet / BNE original name: Status Verdeck Cabrio), 36866=StatusSchluesselSuche (ID_FN_INQY_StatusSchluesselSuche) (BNE original name: Status Schlüssel Suche), 58882=StatusKlimaLuftverteilungFA (ID_FN_INQY_StatusKlimaLuftverteilungFA) (BNE original name: Status Klima Luftverteilung FA), 59906=StatusKlimaLuftverteilungBF (ID_FN_INQY_StatusKlimaLuftverteilungBF) (BNE original name: Status Klima Luftverteilung BF), 60418=StatusKlimaSHSlashZHZusatzwasserpumpe (ID_FN_INQY_StatusKlimaSHSlashZHZusatzwasserpumpe) (BNE original name: Status Klima SH/ZH Zusatzwasserpumpe), 60930=StatusKlimaZusatzprogramme (ID_FN_INQY_StatusKlimaZusatzprogramme) (Wird ab BN2020 nur noch von HMI verwendet / BNE original name: Status Klima Zusatzprogramme), 61442=StatusKlimaStandfunktionen (ID_FN_INQY_StatusKlimaStandfunktionen) (BNE original name: Status Klima Standfunktionen), 63234=EinheitenBN2020 (ID_FN_INQY_EinheitenBN2020) (BNE original name: Einheiten BN2020), 63490=UhrzeitSlashDatum (ID_FN_INQY_UhrzeitSlashDatum) (BNE original name: Uhrzeit/Datum), 3843=StatusServiceCallTeleX (ID_FN_INQY_StatusServiceCallTeleX) (BNE original name: Status Service Call TeleX), 4867=StatusServiceCallTeleservice (ID_FN_INQY_StatusServiceCallTeleservice) (BNE original name: Status Service Call Teleservice), 12803=VerbrauchInformationDaten (ID_FN_INQY_VerbrauchInformationDaten) (BNE original name: Verbrauch Information Daten), 13827=AnzeigeCheckcontrol_Meldung_Rolle_ (ID_FN_INQY_AnzeigeCheckcontrol_Meldung_Rolle_) (BNE original name: Anzeige Checkcontrol-Meldung (Rolle)), 14851=StatusMonitorFront (ID_FN_INQY_StatusMonitorFront) ((E60, RR01) Wird ab BN2020 nur noch von HMI verwendet / (E60, RR01) / BNE original name: Status Monitor Front), 16643=StatusKartendaten (ID_FN_INQY_StatusKartendaten) (BNE original name: Status Kartendaten), 23555=StatusBordcomputerBN2020 (ID_FN_INQY_StatusBordcomputerBN2020) ((E60) / BNE original name: Status Bordcomputer BN2020), 24579=DatenBordcomputer_Fahrtbeginn_ (ID_FN_INQY_DatenBordcomputer_Fahrtbeginn_) ((E60) / BNE original name: Daten Bordcomputer (Fahrtbeginn)), 32771=Fahrgestellnummer (ID_FN_INQY_Fahrgestellnummer), 33027=ElektronischerMotoroelmessstab (ID_FN_INQY_ElektronischerMotoroelmessstab) (BNE original name: Elektronischer Motorölmessstab), 34819=Fahrzeugtyp (ID_FN_INQY_Fahrzeugtyp), 38147=CodierungPowermanagement (ID_FN_INQY_CodierungPowermanagement) (BNE original name: Codierung Powermanagement), 40451=Bedienung_Uhrzeit_Datum (ID_FN_INQY_Bedienung_Uhrzeit_Datum), 43523=Bedienung_Uhrzeit_Datum_UTC (ID_FN_INQY_Bedienung_Uhrzeit_Datum_UTC), 43779=Bedienung_Datum_Winterzeit_Sommerzeit (ID_FN_INQY_Bedienung_Datum_Winterzeit_Sommerzeit), 46595=PositionFensterheberFAT (ID_FN_INQY_PositionFensterheberFAT) (ACHTUNG: Hier wird der CAN-Identifier der Nachricht angegeben, auch wenn die Nachricht beim E60 vom SI-Bus kommt. Die E60-Türelektronik FAT am SI-Bus müssen auf diese Codierung reagieren und die Nachricht Position Fensterheber FAT auf Anfrage raussenden. / ATTENTION:The CAN identifier of the message cannot be given here, even if the message comes from the SI bus with E60. The E60 door electronics DRD on the SI bus must react to this coding and send out the position of window regulator DRD message on request. / BNE original name: Position Fensterheber FAT), 46851=PositionFensterheberFATH (ID_FN_INQY_PositionFensterheberFATH) (BNE original name: Position Fensterheber FATH), 47107=PositionFensterheberBFT (ID_FN_INQY_PositionFensterheberBFT) (ACHTUNG: Hier wird der CAN-Identifier der Nachricht angegeben, auch wenn die Nachricht beim E60 vom SI-Bus kommt. Die E60-Türelektronik BFT am SI-Bus müssen auf diese Codierung reagieren und die Nachricht Position Fensterheber BFT auf Anfrage raussenden. / ATTENTION:The CAN identifier of the message is given here, even if the message comes from the SI bus with E60. The E60 door electronics PSD on the SI bus must react to this coding and send out the position of electric windows PSD message on request. / BNE original name: Position Fensterheber BFT), 47363=PositionFensterheberBFTH (ID_FN_INQY_PositionFensterheberBFTH) (BNE original name: Position Fensterheber BFTH), 47619=PositionSHD (ID_FN_INQY_PositionSHD) (BNE original name: Position SHD), 48131=PositionFensterheberSicherheitsfahrzeug (ID_FN_INQY_PositionFensterheberSicherheitsfahrzeug) (BNE original name: Position Fensterheber Sicherheitsfahrzeug), 48899=PositionFensterheberHeckscheibe (ID_FN_INQY_PositionFensterheberHeckscheibe) (BNE original name: Position Fensterheber Heckscheibe), 49155=KonfigurationFAS (ID_FN_INQY_KonfigurationFAS) (BNE original name: Konfiguration FAS), 49411=KonfigurationBFS (ID_FN_INQY_KonfigurationBFS) (BNE original name: Konfiguration BFS), 49667=KonfigurationFASH (ID_FN_INQY_KonfigurationFASH) (BNE original name: Konfiguration FASH), 49923=KonfigurationBFSH (ID_FN_INQY_KonfigurationBFSH) (BNE original name: Konfiguration BFSH), 53251=StatusSpurverlassenswarnsystemCKM (ID_FN_INQY_StatusSpurverlassenswarnsystemCKM) (BNE original name: Status Spurverlassenswarnsystem CKM), 54531=StatusZentralverriegelungCKM (ID_FN_INQY_StatusZentralverriegelungCKM) (BNE original name: Status Zentralverriegelung CKM), 55043=StatusDWACKM (ID_FN_INQY_StatusDWACKM) (BNE original name: Status DWA CKM), 56067=StatusMemorypositionenCKM (ID_FN_INQY_StatusMemorypositionenCKM) (BNE original name: Status Memorypositionen CKM), 56579=StatusLichtCKM (ID_FN_INQY_StatusLichtCKM) (BNE original name: Status Licht CKM), 57603=StatusALCCKM (ID_FN_INQY_StatusALCCKM) (BNE original name: Status ALC CKM), 58115=StatusHeckklappeCKM (ID_FN_INQY_StatusHeckklappeCKM) (BNE original name: Status Heckklappe CKM), 60163=GrenzwerteSchwenkLinks (ID_FN_INQY_GrenzwerteSchwenkLinks) (BNE original name: Grenzwerte Schwenk Links), 60419=GrenzwerteSchwenkRechts (ID_FN_INQY_GrenzwerteSchwenkRechts) (BNE original name: Grenzwerte Schwenk Rechts), 61699=StatusLichtErweitertCKM (ID_FN_INQY_StatusLichtErweitertCKM) (BNE original name: Status Licht Erweitert CKM), 9731=WirkungsgradInformationData (ID_FN_INQY_WirkungsgradInformationData) (BNE original name: Wirkungsgrad Information Data), 10243=RelativzeitBN2020 (ID_FN_INQY_RelativzeitBN2020) (BNE original name: Relativzeit BN2020), 3588=GPS_Datum_CAN (ID_FN_INQY_GPS_Datum_CAN), 3844=GPS_Uhrzeit_CAN (ID_FN_INQY_GPS_Uhrzeit_CAN), 6660=StatusKonfigurationKombi4 (ID_FN_INQY_StatusKonfigurationKombi4) (BNE original name: Status Konfiguration Kombi 4), 9220=StatusKonfigurationKombi (ID_FN_INQY_StatusKonfigurationKombi) (BNE original name: Status Konfiguration Kombi), 9988=KonfigurationDSC (ID_FN_INQY_KonfigurationDSC) (BNE original name: Konfiguration DSC), 11780=StatusM_Drive2 (ID_FN_INQY_StatusM_Drive2) (BNE original name: Status M-Drive 2), 13316=KonfigurationEPS (ID_FN_INQY_KonfigurationEPS) (BNE original name: Konfiguration EPS), 13572=MessungMotoroel (ID_FN_INQY_MessungMotoroel) (BNE original name: Messung Motoröl), 16132=IdentifikationsnummerSensorcluster (ID_FN_INQY_IdentifikationsnummerSensorcluster) (BNE original name: Identifikationsnummer Sensorcluster), 16642=Status_Hindernis_Tuer (ID_FN_INQY_Status_Hindernis_Tuer), 65535=Signal_unbefuellt (ID_FN_INQY_Signal_unbefuellt), 65533=Reserviert_nicht_verfuegbar (ID_FN_INQY_Reserviert_nicht_verfuegbar) (Hinweis: Reserviert für funktionale Kennung Signal-Tag "Funktionsschnittstelle_ist_nicht_verfuegbar"), 65534=Reserviert_Fehler (ID_FN_INQY_Reserviert_Fehler) (Hinweis: Reserviert für funktionale Kennung Signal-Tag "Funktion_meldet_Fehler")} "ID_Funktion_Anfrage / ID_function_inquiry | Enthält den Identifier der angefragten Nachricht. Es sind nur die Identifier erlaubt, die als anfragbare Nachrichten definiert sind.", to EPS  # ID_Funktion_Anfrage / ID_function_inquiry | LogicalInterface:BMW.INFRASTRUCTURE.COMMUNICATION.InquiryService[external]@Infrastruktur; Dieses Signal löst die bis einschließlich SP2015 gültige Version des gleichnamigen Signales ab. Ab SP2018 darf nur noch diese Version des Signals verwendet werden. Damit wird die in der alten Signalversion existierende Ausnahme bezüglich der Byteorder aufgelöst. Die Darstellung der Signal-Inhalte auf dem Bus wird dadurch jedoch nicht verändert – um dies zu erreichen wurden High-Byte und Low-Byte der Kodierungen vertauscht. Achtung: Sollte es sich sender- oder empfängerseitig um ein reines SP2015-Gleichteil handeln, das demnach die Versendung oder den Empfang des Signals ID_Funktion_Anfrage unverändert zu SP2015 umsetzt, so ist die hier spezifizierte Version des Signals ungültig! Für diese Gleichteile ist die für SP2015 spezifizierte Version dieses Signals gültig. Dieses Signal enthält in der Regel den 11-Bit CAN-Identifier der angefragten Nachricht. Es kann allerdings Abweichungen von dieser Regel geben, z.B. - im Fall von Zuordnungen mehrerer anfragbarer Frames zu einer CAN-ID - im Fall busspezifischer unterschiedlicher CAN-IDs des angefragten Frames - im Fall von Anfragen auf Nicht-CAN Bussen (z.B. FlexRay) - im Fall von 29-Bit CAN-IDs der angefragten Frames Es sind nur die Codierungen erlaubt, zu denen anfragbare PDUs definiert sind. / This signal contains the identifier of the message inquired. Only the identifiers are allowed which are defined as addressable messages. N.B. As regards byte orderings, this signal constitutes an exception because the inquired identifier must be transmitted in Engineola format. In the definite case this means that Byte 1 contains the high byte and Byte 2 the low byte of the desired identifiers [Byte 1, Bit 0: 2^8, Byte 1, Bit 7: 2^15 (= MSEC.B) and Byte 2, Bit 0: 2^0 (= LSB), Byte 2, Bit 7: 2^7]
  pdu DBG_EPS_BS_MOD_58_BYTE: length=58, transmission-mode-true-timing=cyclic-timing=time-period={tolerance=absolute-tolerance=0.004, value=0.02}, unused-bit-pattern=255  # Debug EPS Modus Basis 58 Byte | Diese PDU enthält die 57-Byte langen Debug Information. Die Signale in dieser PDU können durch den Fachbereich eigenständig angepasst werden.
    signal DBG_EPS_BS_MOD_58_BYTE_ID2: start 0, 8 bit, little-endian, init-value=SWITCH_CODE:1, base-type=uint8, transfer-property=PENDING
    signal SYS_ST_EPS: start 8, 4 bit, little-endian, base-type=uint8, compu {identical}, range phys 0..255  # LogicalInterface:BMW.INFRASTRUCTURE.DIAGNOSIS.Debug[internal]@Infrastruktur; Dummy-Signal. Kann beliebig geändert werden.
    signal ST_CON_VEH_EPS: start 12, 4 bit, little-endian, base-type=uint8, compu {identical}, range phys 0..255  # LogicalInterface:BMW.INFRASTRUCTURE.DIAGNOSIS.Debug[internal]@Infrastruktur; Dummy-Signal. Kann beliebig geändert werden.
    signal VEH_SPD_EPS: start 16, 16 bit, little-endian, base-type=uint16, compu {identical}, range phys 0..65535  # LogicalInterface:BMW.INFRASTRUCTURE.DIAGNOSIS.Debug[internal]@Infrastruktur; Dummy-Signal. Kann beliebig geändert werden.
    signal BATT_VLTG_EPS: start 32, 16 bit, little-endian, base-type=uint16, compu {identical}, range phys 0..65535  # LogicalInterface:BMW.INFRASTRUCTURE.DIAGNOSIS.Debug[internal]@Infrastruktur; Dummy-Signal. Kann beliebig geändert werden.
    signal ESTIMD_PEAK_MOT_CURR_EPS: start 48, 24 bit, little-endian, base-type=uint32, compu {identical}, range phys 0..4294967295  # LogicalInterface:BMW.INFRASTRUCTURE.DIAGNOSIS.Debug[internal]@Infrastruktur; Dummy-Signal. Kann beliebig geändert werden.
    signal MOT_VEL_EPS: start 72, 16 bit, little-endian, base-type=uint16, compu {identical}, range phys 0..65535  # LogicalInterface:BMW.INFRASTRUCTURE.DIAGNOSIS.Debug[internal]@Infrastruktur; Dummy-Signal. Kann beliebig geändert werden.
    signal MOT_TQ_CMD_LIMD_EPS: start 88, 16 bit, little-endian, base-type=uint16, compu {identical}, range phys 0..65535  # LogicalInterface:BMW.INFRASTRUCTURE.DIAGNOSIS.Debug[internal]@Infrastruktur; Dummy-Signal. Kann beliebig geändert werden.
    signal PRIM_HW_TQ_SNSR_VLTG_EPS: start 104, 8 bit, little-endian, base-type=uint8, compu {identical}, range phys 0..255  # LogicalInterface:BMW.INFRASTRUCTURE.DIAGNOSIS.Debug[internal]@Infrastruktur; Dummy-Signal. Kann beliebig geändert werden.
    signal SECDRY_HW_TQ_SNSR_VLTG_EPS: start 112, 8 bit, little-endian, base-type=uint8, compu {identical}, range phys 0..255  # LogicalInterface:BMW.INFRASTRUCTURE.DIAGNOSIS.Debug[internal]@Infrastruktur; Dummy-Signal. Kann beliebig geändert werden.
    signal ECU_TEMP_EPS: start 120, 8 bit, little-endian, base-type=uint8, compu {identical}, range phys 0..255  # LogicalInterface:BMW.INFRASTRUCTURE.DIAGNOSIS.Debug[internal]@Infrastruktur; Dummy-Signal. Kann beliebig geändert werden.
    signal MOT_FET_TEMP_EPS: start 128, 8 bit, little-endian, base-type=uint8, compu {identical}, range phys 0..255  # LogicalInterface:BMW.INFRASTRUCTURE.DIAGNOSIS.Debug[internal]@Infrastruktur; Dummy-Signal. Kann beliebig geändert werden.
    signal MOT_MAG_TEMP_EPS: start 136, 8 bit, little-endian, base-type=uint8, compu {identical}, range phys 0..255  # LogicalInterface:BMW.INFRASTRUCTURE.DIAGNOSIS.Debug[internal]@Infrastruktur; Dummy-Signal. Kann beliebig geändert werden.
    signal MOT_WIDG_TEMP_EPS: start 144, 16 bit, little-endian, base-type=uint16, compu {identical}, range phys 0..65535  # LogicalInterface:BMW.INFRASTRUCTURE.DIAGNOSIS.Debug[internal]@Infrastruktur; Dummy-Signal. Kann beliebig geändert werden.
    signal MOT_TQ_CMD_EPS: start 160, 16 bit, little-endian, base-type=uint16, compu {identical}, range phys 0..65535  # LogicalInterface:BMW.INFRASTRUCTURE.DIAGNOSIS.Debug[internal]@Infrastruktur; Dummy-Signal. Kann beliebig geändert werden.
  pdu DBG_EPS_MOD_EXT_120_BYTE: length=58, transmission-mode-true-timing=cyclic-timing=time-period={tolerance=absolute-tolerance=0.001, value=0.005}, unused-bit-pattern=255  # Debug EPS Modus Erweitert 120 Byte | Diese PDU enthält die 119-Byte langen Debug Information. Bei Verwendung dieses Modes muss die Frame Länge vom Fachbereich auf 120-Bytes angepasst werden. Die Signale in dieser PDU können durch den Fachbereich eigenständig angepasst werden.
    signal DBG_EPS_MOD_EXT_120_BYTE: start 8, 8 bit, little-endian, base-type=uint8, compu {identical}, range phys 0..255  # Debug_EPS_Modus_Erweitert_120_Byte / debug_EPS_mode_extended_120_byte | LogicalInterface:BMW.INFRASTRUCTURE.DIAGNOSIS.Debug[internal]@Infrastruktur; Dummy-Signal. Kann beliebig geändert werden.
    signal DBG_EPS_MOD_EXT_120_BYTE_ID2: start 0, 8 bit, little-endian, init-value=SWITCH_CODE:2, base-type=uint8, transfer-property=PENDING
  pdu RQ_STG_EFAN:  # Anforderung Wärmemanagement / Request Stage Electric-Fan
    length=8
    transmission-mode-true-timing=cyclic-timing={time-period={tolerance=absolute-tolerance=0.2, value=1.0}, "Um sicherzustellen, dass das Ende der zyklischen Versendung erkannt wird, muss die Versendung der Stoppnachricht (Signal Anforderung_Steuerung_Elektrolüfter = 0) insgesamt 3-mal mit einem Wiederholzyklus von t=160 ms erfolgen (Details in der Spezifikation: Erweiterung der ereignisgesteuerten Auslösebedingungen). Zusätzlich erfolgt eine zyklische Versendung der Nachricht, wenn die Signale Temperatur_Komponente_Wärmemanagement und ID_Temperatur_Komponente_Wärmemanagement befüllt sind."}
    unused-bit-pattern=255
    signal ID_FN_RQ_STG_EFAN: start 8, 8 bit, little-endian, base-type=uint8, invalid-value=value_255Dot0:255, compu {1=AFS_Anforderung (ID_FN_RQ_STG_EFAN_AFS_Anforderung) (Diese Nachricht darf vom AFS ausschließlich zum Bauteilschutz im Notfall versandt werden! Anforderung wird vom E6x/PL2/PL4 AFS nicht mehr versendet. / BNE original name: AFS-Anforderung), 2=EPS_Anforderung (ID_FN_RQ_STG_EFAN_EPS_Anforderung) (Diese Nachricht darf vom EPS ausschließlich zum Bauteilschutz im Notfall versandt werden! / BNE original name: EPS-Anforderung), 3=DSC_Anforderung (ID_FN_RQ_STG_EFAN_DSC_Anforderung) (Diese Nachricht darf vom DSC ausschließlich zum Bauteilschutz im Notfall versandt werden! / BNE original name: DSC-Anforderung), 4=Servotronic_Anforderung (ID_FN_RQ_STG_EFAN_Servotronic_Anforderung) (Diese Kodierung wird _nicht_ in den Baureihen L1 bis L5 verwendet. Diese Nachricht darf ausschließlich zum Bauteilschutz im Notfall versandt werden! / BNE original name: Servotronic-Anforderung), 255=SignalUngueltig (ID_FN_RQ_STG_EFAN_SignalUngueltig) (BNE original name: Signal ungültig)} "ID_Funktion_Anforderung_Stufe_Elektrolüfter / ID_function_request_stage_electric-fan | Automatisch generiert (Migration 2004-10-30)"  # ID_Funktion_Anforderung_Stufe_Elektrolüfter / ID_function_request_stage_electric-fan | LogicalInterface:BMW.POWERTRAIN.ENGINE.COMBUSTION.HeatManagement[internal]@Fahren; Dieses Signal gibt den Anforderer der gewünschten Elektrolüfterstufe an.
    signal ID_TEMP_CPO_HET_MNG: start 20, 4 bit, little-endian, base-type=uint8, invalid-value=value_15Dot0:15, compu {1=EPS_Motortemperatur (ID_TEMP_CPO_HET_MNG_EPS_Motortemperatur) (BNE original name: EPS-Motortemperatur), 13=Reserviert (ID_TEMP_CPO_HET_MNG_Reserviert) (Hinweis: Reserviert für funktionale Kennung Signal-Tag.), 14=Reserviert_bne_FCE0E84AD43C48B79F8D9B411125541C_14 (ID_TEMP_CPO_HET_MNG_Reserviert_bne_FCE0E84AD43C48B79F8D9B411125541C_14) (Hinweis: Reserviert für funktionale Kennung Signal-Tag. / BNE original name: Reserviert), 15=Signal_unbefuellt (ID_TEMP_CPO_HET_MNG_Signal_unbefuellt) (Sendefunktion nicht in Betrieb)} "ID_Temperatur_Komponente_Wärme_Management / ID_temperature_component_heat_management"  # ID_Temperatur_Komponente_Wärme_Management / ID_temperature_component_heat_management | LogicalInterface:BMW.POWERTRAIN.ENGINE.COMBUSTION.HeatManagement[internal]@Fahren; Dieses Signal gibt die Komponente für das Temperatursignal für das Motorwärmemanagement an. Dieses Signal wird in 444, F15-F16, F25 und F25_ab_PU12-07 nicht ausgewertet.
    signal RQ_STG_EFAN: start 16, 4 bit, little-endian, base-type=uint8, invalid-value=value_15Dot0:15, compu {0=AUS (RQ_STG_EFAN_AUS), 1=Stufe (RQ_STG_EFAN_Stufe), 15=SignalUngueltig (RQ_STG_EFAN_SignalUngueltig) (BNE original name: Signal ungültig)} "Anforderung_Stufe_Elektrolüfter / request_stage_electric-fan | Automatisch generiert (Migration 2004-10-30)"  # Anforderung_Stufe_Elektrolüfter / request_stage_electric-fan | LogicalInterface:BMW.POWERTRAIN.ENGINE.COMBUSTION.HeatManagement[internal]@Fahren; Die Stufen werden als Luftmassenstrom interpretiert. Die Stufe 14 entspricht der maximalen Luftmassenstromanforderung.
    signal RQ_STG_EFAN_ID2: start 0, 8 bit, little-endian, init-value=SWITCH_CODE:21, base-type=uint8, transfer-property=PENDING
    signal TEMP_CPO_HET_MNG: start 24, 8 bit, little-endian, base-type=uint8, invalid-value=value_255Dot0:255, compu {phys=raw-48 for raw 48..300, 253=Reserviert (TEMP_CPO_HET_MNG_Reserviert) (Hinweis: Reserviert für funktionale Kennung Signal-Tag.), 254=Reserviert_bne_13E59F6816364760A116813207E86FA4_254 (TEMP_CPO_HET_MNG_Reserviert_bne_13E59F6816364760A116813207E86FA4_254) (Hinweis: Reserviert für funktionale Kennung Signal-Tag. / BNE original name: Reserviert), 255=Signal_unbefuellt (TEMP_CPO_HET_MNG_Signal_unbefuellt) (Sendefunktion nicht in Betrieb); unit DegCgrd} "Temperatur_Komponente_Wärme_Management / temperature_component_heat_management", range phys 0..252 DegCgrd "Temperatur_Komponente_Wärme_Management / temperature_component_heat_management"  # Temperatur_Komponente_Wärme_Management / temperature_component_heat_management | LogicalInterface:BMW.POWERTRAIN.ENGINE.COMBUSTION.HeatManagement[internal]@Fahren; Komponententemperatur für das Motorwärmemanagement Dieses Signal wird in 444, F15-F16, F25 und F25_ab_PU12-07 nicht ausgewertet.
  pdu SECU_CHAL: length=8, minimum-delay=0.05, transmission-mode-true-timing=event-controlled-timing=number-of-repetitions=0, unused-bit-pattern=255  # Sicher Challenge | $(AUTOSAR; SIGNALGROUP)
    signal SECU_CHAL: start 24, 40 bit, little-endian, base-type=uint64, invalid-value=value_1Dot099511627775E12:1099511627775, compu {identical}, range phys 0..1099511627775  # Sicher_Challenge / secure_challenge | LogicalInterface:BMW.INFRASTRUCTURE.COMMUNICATION.SecureChallengeResponse[internal]@Infrastruktur;
    signal SECU_CHAL_ID2: start 0, 8 bit, little-endian, init-value=SWITCH_CODE:248, base-type=uint8, transfer-property=PENDING
    signal SSS_IDENT_CHAL: start 16, 8 bit, little-endian, base-type=uint8, invalid-value=value_255Dot0:255, compu {0=ZGWVIN (SSS_IDENT_ZGWVIN) (BNE original name: ZGW VIN), 255=SignalUngueltig (SSS_IDENT_SignalUngueltig) (BNE original name: Signal ungültig)} "SSS_Identifikation / SSS_identification"  # SSS_Identifikation_Challenge / SSS_identification_challenge | LogicalInterface:BMW.INFRASTRUCTURE.COMMUNICATION.SecureChallengeResponse[internal]@Infrastruktur;
    signal SSV_IDENT_CHAL: start 8, 8 bit, little-endian, base-type=uint8, invalid-value=value_255Dot0:255, compu-method=SSV_IDENT  # SSV_Identifikation_Challenge / SSV_identification_challenge | LogicalInterface:BMW.INFRASTRUCTURE.COMMUNICATION.SecureChallengeResponse[internal]@Infrastruktur;
  pdu SECU_RESP: length=8, minimum-delay=0.05, transmission-mode-true-timing=event-controlled-timing=number-of-repetitions=0, unused-bit-pattern=255  # Sicher Response | $(AUTOSAR; SIGNALGROUP)
    signal COU_BS_RESP: start 16, 24 bit, little-endian, base-type=uint32, invalid-value=value_1Dot6777215E7:16777215, compu {identical}, range phys 0..16777214, to EPS  # Zähler_Basis_Response / counter_base_response | LogicalInterface:BMW.INFRASTRUCTURE.COMMUNICATION.SecureChallengeResponse[internal]@Infrastruktur;
    signal SECU_RESP_ID2: start 0, 8 bit, little-endian, init-value=SWITCH_CODE:247, base-type=uint8, transfer-property=PENDING, to EPS
    signal SSV_IDENT_RESP: start 8, 8 bit, little-endian, base-type=uint8, invalid-value=value_255Dot0:255, compu-method=SSV_IDENT, to EPS  # SSV_Identifikation_Response / SSV_identification_response | LogicalInterface:BMW.INFRASTRUCTURE.COMMUNICATION.SecureChallengeResponse[internal]@Infrastruktur;
    signal STU_RESP: start 40, 24 bit, little-endian, base-type=uint32, invalid-value=value_1Dot6777215E7:16777215, compu {identical}, range phys 0..16777215, to EPS  # Signatur_Response / signature_response | LogicalInterface:BMW.INFRASTRUCTURE.COMMUNICATION.SecureChallengeResponse[internal]@Infrastruktur;
